VERSION ""

NS_ :

BS_:

BU_: ICC_ICE DVR EPC BBCM PCL PLG EAMP CMSM SBOX AVAS FLZCU RXCU_HCU CGW TBOX BNCM CWC FRZCU

BO_ 819 ADS_4: 48 CGW
 SG_ ADS_4_CRC1 : 7|8@0+ (1,0) [0|255] ""  ICC_ICE
 SG_ ADS_4_RollgCntr1 : 11|4@0+ (1,0) [0|14] ""  ICC_ICE
 SG_ ADS_4_Resd1 : 15|4@0+ (1,0) [0|15] ""  ICC_ICE
 SG_ ADS_4_AEBStatus : 19|3@0+ (1,0) [0|7] ""  ICC_ICE
 SG_ ADS_4_ACCSts : 23|4@0+ (1,0) [0|15] ""  ICC_ICE
 SG_ ADS_4_TimeGapSet : 26|3@0+ (1,0) [0|7] ""  ICC_ICE
 SG_ ADS_4_FcwMode : 29|3@0+ (1,0) [0|7] ""  ICC_ICE
 SG_ ADS_4_AEBReqType : 16|3@0+ (1,0) [0|7] ""  ICC_ICE
 SG_ ADS_4_SetSpd : 39|8@0+ (1,0) [0|255] "kph"  ICC_ICE
 SG_ ADS_4_DAIStatus : 41|2@0+ (1,0) [0|3] ""  ICC_ICE
 SG_ ADS_4_ACCTextMessage : 45|4@0+ (1,0) [0|15] ""  ICC_ICE
 SG_ ADS_4_LongiTakeOverReq : 46|1@0+ (1,0) [0|1] ""  ICC_ICE
 SG_ ADS_4_SetSpdUnit : 47|1@0+ (1,0) [0|1] ""  ICC_ICE
 SG_ ADS_4_GoNotifier : 50|3@0+ (1,0) [0|7] ""  ICC_ICE
 SG_ ADS_4_DAISts : 52|2@0+ (1,0) [0|3] ""  ICC_ICE
 SG_ ADS_4_Radar_textinfo : 55|3@0+ (1,0) [0|7] ""  ICC_ICE
 SG_ ADS_4_SCF_PopoverReq : 57|1@0+ (1,0) [0|1] ""  ICC_ICE
 SG_ ADS_4_DrvrCfmSCFDispFb : 58|1@0+ (1,0) [0|1] ""  ICC_ICE
 SG_ ADS_4_SCF_SpdLimUnit : 60|2@0+ (1,0) [0|3] ""  ICC_ICE
 SG_ ADS_4_SCF_SpdLimSts : 63|3@0+ (1,0) [0|7] ""  ICC_ICE
 SG_ ADS_4_CRC2 : 71|8@0+ (1,0) [0|255] ""  ICC_ICE
 SG_ ADS_4_RollgCntr2 : 75|4@0+ (1,0) [0|14] ""  ICC_ICE
 SG_ ADS_4_Resd2 : 79|4@0+ (1,0) [0|15] ""  ICC_ICE
 SG_ ADS_4_ACCObjTyp : 83|4@0+ (1,0) [0|15] ""  ICC_ICE
 SG_ ADS_4_FrntFarObjTyp : 87|4@0+ (1,0) [0|15] ""  ICC_ICE
 SG_ ADS_4_ACCObjLgtDstX : 95|8@0+ (0.5,0) [0|127] "m"  ICC_ICE
 SG_ ADS_4_FrntFarObjID : 107|1@0+ (1,0) [0|1] ""  ICC_ICE
 SG_ ADS_4_Resd : 108|1@0+ (1,0) [0|1] ""  ICC_ICE
 SG_ ADS_4_ACCObjID : 109|1@0+ (1,0) [0|1] ""  ICC_ICE
 SG_ ADS_4_ACCObjHozDstY : 103|10@0+ (0.1,-50) [-50|50] "m"  ICC_ICE
 SG_ ADS_4_FrntFarObjHozDstY : 105|10@0+ (0.1,-50) [-50|50] "m"  ICC_ICE
 SG_ ADS_4_FrntFarObjLgtDstX : 127|8@0+ (0.5,0) [0|127] "m"  ICC_ICE
 SG_ ADS_4_CRC3 : 135|8@0+ (1,0) [0|255] ""  ICC_ICE
 SG_ ADS_4_RollgCntr3 : 139|4@0+ (1,0) [0|14] ""  ICC_ICE
 SG_ ADS_4_Resd3 : 143|4@0+ (1,0) [0|15] ""  ICC_ICE
 SG_ ADS_4_Resd_1 : 146|1@0+ (1,0) [0|1] ""  ICC_ICE
 SG_ ADS_4_LeObjID : 147|1@0+ (1,0) [0|1] ""  ICC_ICE
 SG_ ADS_4_LeObjTyp : 151|4@0+ (1,0) [0|15] ""  ICC_ICE
 SG_ ADS_4_LeObjHozDstY : 145|10@0+ (0.1,-50) [-50|50] "m"  ICC_ICE
 SG_ ADS_4_LeObjLgtDstX : 167|8@0+ (0.5,0) [0|127] "m"  ICC_ICE
 SG_ ADS_4_RiObjID : 171|1@0+ (1,0) [0|1] ""  ICC_ICE
 SG_ ADS_4_RiObjTyp : 175|4@0+ (1,0) [0|15] ""  ICC_ICE
 SG_ ADS_4_RiObjHozDstY : 169|10@0+ (0.1,-50) [-50|50] "m"  ICC_ICE
 SG_ ADS_4_RiObjLgtDstX : 191|8@0+ (0.5,0) [0|127] "m"  ICC_ICE
 SG_ ADS_4_CRC4 : 199|8@0+ (1,0) [0|255] ""  ICC_ICE
 SG_ ADS_4_RollgCntr4 : 203|4@0+ (1,0) [0|14] ""  ICC_ICE
 SG_ ADS_4_Resd4 : 207|4@0+ (1,0) [0|15] ""  ICC_ICE
 SG_ ADS_4_SCFSwtSet : 210|2@0+ (1,0) [0|3] ""  ICC_ICE
 SG_ ADS_4_AEBSettingSt : 212|2@0+ (1,0) [0|3] ""  ICC_ICE
 SG_ ADS_4_FCWSettingSt : 215|3@0+ (1,0) [0|7] ""  ICC_ICE
 SG_ ADS_4_DAISwtSet : 223|2@0+ (1,0) [0|3] ""  ICC_ICE
 SG_ ADS_4_CruiseAccelerateSts : 221|2@0+ (1,0) [0|3] ""  ICC_ICE

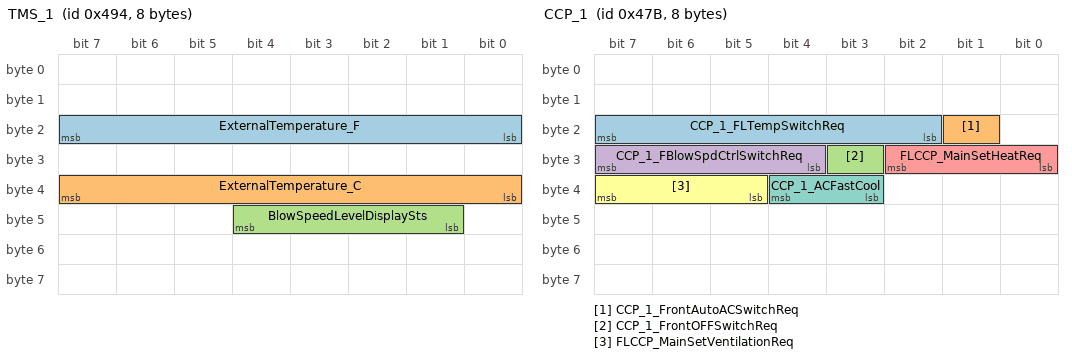
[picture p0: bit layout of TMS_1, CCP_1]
BO_ 1172 TMS_1: 8 CGW
 SG_ ExternalTemperature_F : 23|8@0+ (1,-67) [-67|158] "°F"  ICC_ICE,EPC
 SG_ ExternalTemperature_C : 39|8@0+ (0.5,-40) [-40|85] "°C"  ICC_ICE,EPC
 SG_ BlowSpeedLevelDisplaySts : 44|4@0+ (1,0) [0|15] ""  ICC_ICE,EAMP

BO_ 1147 CCP_1: 8 CGW
 SG_ CCP_1_FLTempSwitchReq : 23|6@0+ (0.5,15.5) [15.5|30.5] "℃"  ICC_ICE
 SG_ CCP_1_FrontAutoACSwitchReq : 17|1@0+ (1,0) [0|1] ""  ICC_ICE
 SG_ CCP_1_FrontOFFSwitchReq : 27|1@0+ (1,0) [0|1] ""  ICC_ICE
 SG_ CCP_1_FBlowSpdCtrlSwitchReq : 31|4@0+ (1,0) [0|15] ""  ICC_ICE
 SG_ FLCCP_MainSetHeatReq : 26|3@0+ (1,0) [0|7] ""  ICC_ICE
 SG_ FLCCP_MainSetVentilationReq : 39|3@0+ (1,0) [0|7] ""  ICC_ICE
 SG_ CCP_1_ACFastCool : 36|2@0+ (1,0) [0|3] ""  ICC_ICE

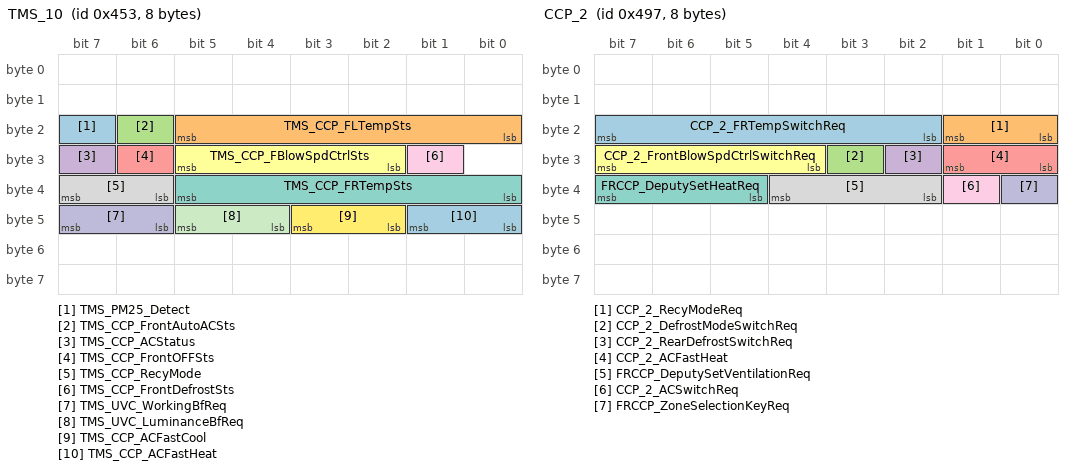
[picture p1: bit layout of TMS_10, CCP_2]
BO_ 1107 TMS_10: 8 CGW
 SG_ TMS_PM25_Detect : 23|1@0+ (1,0) [0|1] ""  ICC_ICE
 SG_ TMS_CCP_FLTempSts : 21|6@0+ (0.5,15.5) [15.5|30.5] "℃"  ICC_ICE
 SG_ TMS_CCP_FrontAutoACSts : 22|1@0+ (1,0) [0|1] ""  ICC_ICE
 SG_ TMS_CCP_ACStatus : 31|1@0+ (1,0) [0|1] ""  ICC_ICE
 SG_ TMS_CCP_FrontOFFSts : 30|1@0+ (1,0) [0|1] ""  ICC_ICE
 SG_ TMS_CCP_FBlowSpdCtrlSts : 29|4@0+ (1,0) [0|15] ""  ICC_ICE
 SG_ TMS_CCP_FRTempSts : 37|6@0+ (0.5,15.5) [15.5|30.5] "℃"  ICC_ICE
 SG_ TMS_CCP_RecyMode : 39|2@0+ (1,0) [0|3] ""  ICC_ICE
 SG_ TMS_CCP_FrontDefrostSts : 25|1@0+ (1,0) [0|1] ""  ICC_ICE
 SG_ TMS_UVC_WorkingBfReq : 47|2@0+ (1,0) [0|3] ""  ICC_ICE
 SG_ TMS_UVC_LuminanceBfReq : 45|2@0+ (1,0) [0|3] ""  ICC_ICE
 SG_ TMS_CCP_ACFastCool : 43|2@0+ (1,0) [0|3] ""  ICC_ICE
 SG_ TMS_CCP_ACFastHeat : 41|2@0+ (1,0) [0|3] ""  ICC_ICE

BO_ 1175 CCP_2: 8 CGW
 SG_ CCP_2_FRTempSwitchReq : 23|6@0+ (0.5,15.5) [15.5|30.5] "℃"  ICC_ICE
 SG_ CCP_2_RecyModeReq : 17|2@0+ (1,0) [0|3] ""  ICC_ICE
 SG_ CCP_2_DefrostModeSwitchReq : 27|1@0+ (1,0) [0|1] ""  ICC_ICE
 SG_ CCP_2_RearDefrostSwitchReq : 26|1@0+ (1,0) [0|1] ""  ICC_ICE
 SG_ CCP_2_ACFastHeat : 25|2@0+ (1,0) [0|3] ""  ICC_ICE
 SG_ CCP_2_FrontBlowSpdCtrlSwitchReq : 31|4@0+ (1,0) [0|15] ""  ICC_ICE
 SG_ FRCCP_DeputySetHeatReq : 39|3@0+ (1,0) [0|7] ""  ICC_ICE
 SG_ FRCCP_DeputySetVentilationReq : 36|3@0+ (1,0) [0|7] ""  ICC_ICE
 SG_ CCP_2_ACSwitchReq : 33|1@0+ (1,0) [0|1] ""  ICC_ICE
 SG_ FRCCP_ZoneSelectionKeyReq : 32|1@0+ (1,0) [0|1] ""  ICC_ICE

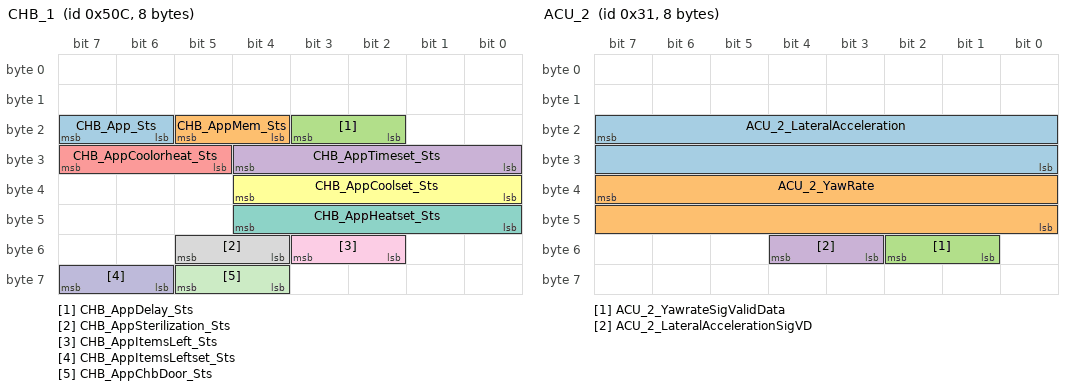
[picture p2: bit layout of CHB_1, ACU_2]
BO_ 1292 CHB_1: 8 CGW
 SG_ CHB_App_Sts : 23|2@0+ (1,0) [0|3] ""  ICC_ICE
 SG_ CHB_AppMem_Sts : 21|2@0+ (1,0) [0|3] ""  ICC_ICE
 SG_ CHB_AppDelay_Sts : 19|2@0+ (1,0) [0|3] ""  ICC_ICE
 SG_ CHB_AppTimeset_Sts : 28|5@0+ (1,0) [0|31] "h"  ICC_ICE
 SG_ CHB_AppCoolorheat_Sts : 31|3@0+ (1,0) [0|7] ""  ICC_ICE
 SG_ CHB_AppCoolset_Sts : 36|5@0+ (1,0) [0|31] ""  ICC_ICE
 SG_ CHB_AppHeatset_Sts : 44|5@0+ (1,0) [0|31] ""  ICC_ICE
 SG_ CHB_AppSterilization_Sts : 53|2@0+ (1,0) [0|3] ""  ICC_ICE
 SG_ CHB_AppItemsLeft_Sts : 51|2@0+ (1,0) [0|3] ""  ICC_ICE
 SG_ CHB_AppItemsLeftset_Sts : 63|2@0+ (1,0) [0|3] ""  ICC_ICE
 SG_ CHB_AppChbDoor_Sts : 61|2@0+ (1,0) [0|3] ""  ICC_ICE

BO_ 49 ACU_2: 8 CGW
 SG_ ACU_2_LateralAcceleration : 23|16@0+ (0.001,-2) [-2|2] "g"  ICC_ICE
 SG_ ACU_2_YawRate : 39|16@0+ (0.01,-180) [-180|180] "deg/sec"  ICC_ICE
 SG_ ACU_2_YawrateSigValidData : 50|2@0+ (1,0) [0|3] ""  ICC_ICE
 SG_ ACU_2_LateralAccelerationSigVD : 52|2@0+ (1,0) [0|3] ""  ICC_ICE

BO_ 1024 FRZCU_13: 64 CGW
 SG_ CSunshadeSts : 23|3@0+ (1,0) [0|7] ""  ICC_ICE
 SG_ CSunshadePercentSts : 20|4@0+ (1,0) [0|15] ""  ICC_ICE
 SG_ FRZCU_SeatHeatLvlFR2 : 31|4@0+ (1,0) [0|15] ""  ICC_ICE
 SG_ FRZCU_SeatVentLvlFR2 : 27|4@0+ (1,0) [0|15] ""  ICC_ICE
 SG_ FRZCU_SeatVentLvlRR2 : 39|4@0+ (1,0) [0|15] ""  ICC_ICE
 SG_ FRZCU_SeatHeatLvlRR2 : 35|4@0+ (1,0) [0|15] ""  ICC_ICE
 SG_ FRZCU_ContainerlightSts : 47|2@0+ (1,0) [0|3] ""  ICC_ICE
 SG_ FRZCU_FRWinThermalSts : 45|1@0+ (1,0) [0|1] ""  ICC_ICE
 SG_ FRZCU_RRWinThermalSts : 44|1@0+ (1,0) [0|1] ""  ICC_ICE
 SG_ FRZCU_CSunshadeThermalSts : 43|1@0+ (1,0) [0|1] ""  ICC_ICE
 SG_ FRZCU_ADSLightSts : 49|2@0+ (1,0) [0|3] ""  ICC_ICE
 SG_ FRZCU_PasgerSeatMovFailCause : 61|4@0+ (1,0) [0|15] ""  ICC_ICE
 SG_ FRZCU_QueenSeatEnterSts : 57|2@0+ (1,0) [0|3] ""  ICC_ICE
 SG_ FRZCU_QueenSeatMovFailCause : 87|4@0+ (1,0) [0|15] ""  ICC_ICE
 SG_ FRZCU_QueenSeatSts : 83|2@0+ (1,0) [0|3] ""  ICC_ICE,BBCM
 SG_ CSunshadeLearnedSts : 93|2@0+ (1,0) [0|3] ""  ICC_ICE
 SG_ CSunshadePosn : 103|7@0+ (1,0) [0|100] "%"  ICC_ICE
 SG_ FRZCU_OnekeyHVoffSwtst : 41|2@0+ (1,0) [0|3] ""  ICC_ICE

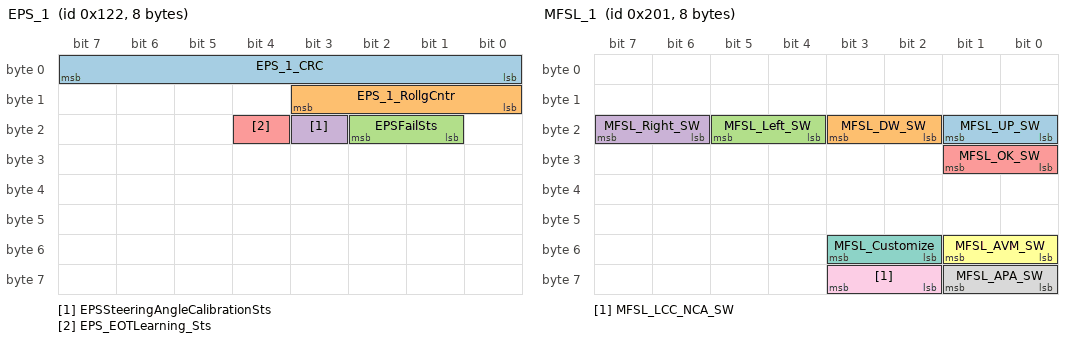
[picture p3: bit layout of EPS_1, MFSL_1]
BO_ 290 EPS_1: 8 CGW
 SG_ EPS_1_CRC : 7|8@0+ (1,0) [0|255] ""  ICC_ICE
 SG_ EPS_1_RollgCntr : 11|4@0+ (1,0) [0|14] ""  ICC_ICE
 SG_ EPSFailSts : 18|2@0+ (1,0) [0|3] ""  ICC_ICE
 SG_ EPSSteeringAngleCalibrationSts : 19|1@0+ (1,0) [0|1] ""  ICC_ICE
 SG_ EPS_EOTLearning_Sts : 20|1@0+ (1,0) [0|1] ""  ICC_ICE

BO_ 513 MFSL_1: 8 CGW
 SG_ MFSL_UP_SW : 17|2@0+ (1,0) [0|3] ""  ICC_ICE
 SG_ MFSL_DW_SW : 19|2@0+ (1,0) [0|3] ""  ICC_ICE
 SG_ MFSL_Left_SW : 21|2@0+ (1,0) [0|3] ""  ICC_ICE
 SG_ MFSL_Right_SW : 23|2@0+ (1,0) [0|3] ""  ICC_ICE
 SG_ MFSL_OK_SW : 25|2@0+ (1,0) [0|3] ""  ICC_ICE
 SG_ MFSL_AVM_SW : 49|2@0+ (1,0) [0|3] ""  ICC_ICE
 SG_ MFSL_Customize : 51|2@0+ (1,0) [0|3] ""  ICC_ICE
 SG_ MFSL_APA_SW : 57|2@0+ (1,0) [0|3] ""  ICC_ICE
 SG_ MFSL_LCC_NCA_SW : 59|2@0+ (1,0) [0|3] ""  ICC_ICE

BO_ 1152 TBOX_8: 16 CGW
 SG_ TBOX_PetmodeSetTemperature : 118|5@0+ (0.5,15.5) [15.5|30.5] "℃"  ICC_ICE

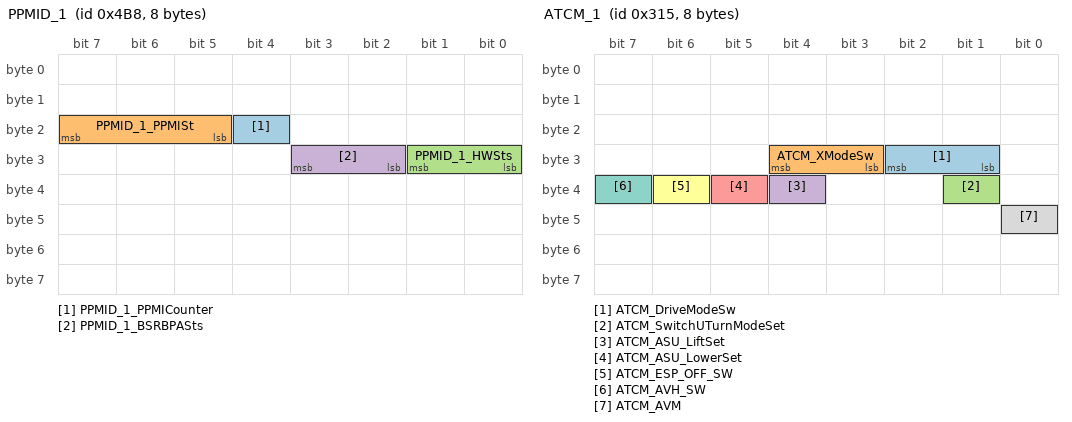
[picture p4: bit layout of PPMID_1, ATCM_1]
BO_ 1208 PPMID_1: 8 CGW
 SG_ PPMID_1_PPMICounter : 20|1@0+ (1,0) [0|1] ""  ICC_ICE
 SG_ PPMID_1_PPMISt : 23|3@0+ (1,0) [0|7] ""  ICC_ICE
 SG_ PPMID_1_HWSts : 25|2@0+ (1,0) [0|3] ""  ICC_ICE
 SG_ PPMID_1_BSRBPASts : 27|2@0+ (1,0) [0|3] ""  ICC_ICE

BO_ 794 ADS_COM_3: 24 CGW
 SG_ ADS_3_ICAStatus : 23|3@0+ (1,0) [0|7] ""  ICC_ICE
 SG_ ADS_3_ICATextinfo : 19|4@0+ (1,0) [0|15] ""  ICC_ICE
 SG_ ADS_3_ACCSts : 31|4@0+ (1,0) [0|15] ""  ICC_ICE
 SG_ ADS_3_DriverHandsoffWarning : 27|3@0+ (1,0) [0|7] ""  ICC_ICE
 SG_ ADS_3_LKSMod : 36|2@0+ (1,0) [0|3] ""  ICC_ICE
 SG_ ADS_3_LKSSts : 34|3@0+ (1,0) [0|7] ""  ICC_ICE
 SG_ ADS_3_ELKSts : 47|3@0+ (1,0) [0|7] ""  ICC_ICE
 SG_ ADS_3_LKSLeftTrackingSt : 44|2@0+ (1,0) [0|3] ""  ICC_ICE
 SG_ ADS_3_LKSRightTrackingSt : 42|2@0+ (1,0) [0|3] ""  ICC_ICE
 SG_ ADS_3_ELKLeftActiveSt : 55|2@0+ (1,0) [0|3] ""  ICC_ICE
 SG_ ADS_3_ELKRightActiveSt : 53|2@0+ (1,0) [0|3] ""  ICC_ICE

BO_ 1155 ASU_3: 16 CGW
 SG_ ASU_3_horizontalSts : 55|2@0+ (1,0) [0|3] ""  ICC_ICE
 SG_ ASU_3_horizontalmodeFb : 58|3@0+ (1,0) [0|7] ""  ICC_ICE

BO_ 789 ATCM_1: 8 CGW
 SG_ ATCM_DriveModeSw : 26|2@0+ (1,0) [0|3] ""  ICC_ICE
 SG_ ATCM_XModeSw : 28|2@0+ (1,0) [0|3] ""  ICC_ICE
 SG_ ATCM_SwitchUTurnModeSet : 33|1@0+ (1,0) [0|1] ""  ICC_ICE
 SG_ ATCM_ASU_LiftSet : 36|1@0+ (1,0) [0|1] ""  ICC_ICE
 SG_ ATCM_ASU_LowerSet : 37|1@0+ (1,0) [0|1] ""  ICC_ICE
 SG_ ATCM_ESP_OFF_SW : 38|1@0+ (1,0) [0|1] ""  ICC_ICE
 SG_ ATCM_AVH_SW : 39|1@0+ (1,0) [0|1] ""  ICC_ICE
 SG_ ATCM_AVM : 40|1@0+ (1,0) [0|1] ""  ICC_ICE

BO_ 1214 BNCM_16: 32 CGW
 SG_ BNCM_16_CRC1 : 7|8@0+ (1,0) [0|255] ""  ICC_ICE
 SG_ BNCM_16_RollgCntr1 : 11|4@0+ (1,0) [0|14] ""  ICC_ICE
 SG_ BNCM_16_Resd1 : 15|4@0+ (1,0) [0|15] ""  ICC_ICE
 SG_ BNCM_16_CMD : 23|16@0+ (1,0) [0|65535] ""  ICC_ICE
 SG_ BNCM_16_PDU1 : 39|64@0+ (1,0) [0|1.84467440737096E+19] ""  ICC_ICE
 SG_ BNCM_16_PDU2 : 103|64@0+ (1,0) [0|1.84467440737096E+19] ""  ICC_ICE
 SG_ BNCM_16_PDU3 : 167|64@0+ (1,0) [0|1.84467440737096E+19] ""  ICC_ICE
 SG_ BNCM_16_PDU4 : 231|32@0+ (1,0) [0|4294967295] ""  ICC_ICE

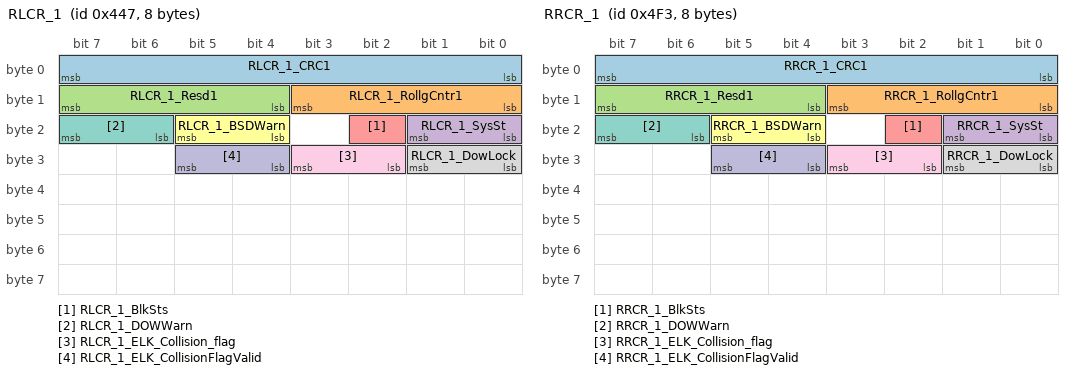
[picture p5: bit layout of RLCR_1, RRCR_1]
BO_ 1095 RLCR_1: 8 CGW
 SG_ RLCR_1_CRC1 : 7|8@0+ (1,0) [0|255] ""  ICC_ICE
 SG_ RLCR_1_RollgCntr1 : 11|4@0+ (1,0) [0|14] ""  ICC_ICE
 SG_ RLCR_1_Resd1 : 15|4@0+ (1,0) [0|15] ""  ICC_ICE
 SG_ RLCR_1_SysSt : 17|2@0+ (1,0) [0|3] ""  ICC_ICE
 SG_ RLCR_1_BlkSts : 18|1@0+ (1,0) [0|1] ""  ICC_ICE
 SG_ RLCR_1_BSDWarn : 21|2@0+ (1,0) [0|3] ""  ICC_ICE
 SG_ RLCR_1_DOWWarn : 23|2@0+ (1,0) [0|3] ""  ICC_ICE
 SG_ RLCR_1_DowLock : 25|2@0+ (1,0) [0|3] ""  ICC_ICE
 SG_ RLCR_1_ELK_Collision_flag : 27|2@0+ (1,0) [0|3] ""  ICC_ICE
 SG_ RLCR_1_ELK_CollisionFlagValid : 29|2@0+ (1,0) [0|3] ""  ICC_ICE

BO_ 1267 RRCR_1: 8 CGW
 SG_ RRCR_1_CRC1 : 7|8@0+ (1,0) [0|255] ""  ICC_ICE
 SG_ RRCR_1_RollgCntr1 : 11|4@0+ (1,0) [0|14] ""  ICC_ICE
 SG_ RRCR_1_Resd1 : 15|4@0+ (1,0) [0|15] ""  ICC_ICE
 SG_ RRCR_1_SysSt : 17|2@0+ (1,0) [0|3] ""  ICC_ICE
 SG_ RRCR_1_BlkSts : 18|1@0+ (1,0) [0|1] ""  ICC_ICE
 SG_ RRCR_1_BSDWarn : 21|2@0+ (1,0) [0|3] ""  ICC_ICE
 SG_ RRCR_1_DOWWarn : 23|2@0+ (1,0) [0|3] ""  ICC_ICE
 SG_ RRCR_1_DowLock : 25|2@0+ (1,0) [0|3] ""  ICC_ICE
 SG_ RRCR_1_ELK_Collision_flag : 27|2@0+ (1,0) [0|3] ""  ICC_ICE
 SG_ RRCR_1_ELK_CollisionFlagValid : 29|2@0+ (1,0) [0|3] ""  ICC_ICE

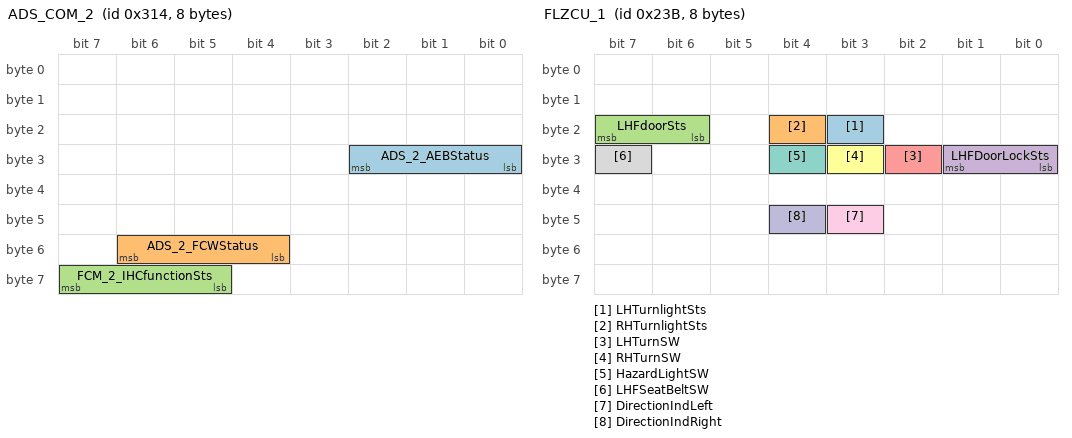
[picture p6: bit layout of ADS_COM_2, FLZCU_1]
BO_ 788 ADS_COM_2: 8 CGW
 SG_ ADS_2_AEBStatus : 26|3@0+ (1,0) [0|6] ""  ICC_ICE
 SG_ ADS_2_FCWStatus : 54|3@0+ (1,0) [0|7] ""  ICC_ICE
 SG_ FCM_2_IHCfunctionSts : 63|3@0+ (1,0) [0|7] ""  ICC_ICE

BO_ 571 FLZCU_1: 8 FLZCU
 SG_ LHTurnlightSts : 19|1@0+ (1,0) [0|1] ""  ICC_ICE,DVR
 SG_ RHTurnlightSts : 20|1@0+ (1,0) [0|1] ""  ICC_ICE,DVR
 SG_ LHFdoorSts : 23|2@0+ (1,0) [0|3] ""  ICC_ICE,EPC,BBCM,PCL,PLG,CMSM
 SG_ LHFDoorLockSts : 25|2@0+ (1,0) [0|3] ""  ICC_ICE,EPC,BBCM,PCL,PLG
 SG_ LHTurnSW : 26|1@0+ (1,0) [0|1] ""  ICC_ICE
 SG_ RHTurnSW : 27|1@0+ (1,0) [0|1] ""  ICC_ICE
 SG_ HazardLightSW : 28|1@0+ (1,0) [0|1] ""  ICC_ICE
 SG_ LHFSeatBeltSW : 31|1@0+ (1,0) [0|1] ""  ICC_ICE
 SG_ DirectionIndLeft : 43|1@0+ (1,0) [0|1] ""  ICC_ICE
 SG_ DirectionIndRight : 44|1@0+ (1,0) [0|1] ""  ICC_ICE

BO_ 699 RZCU_2: 8 FLZCU
 SG_ LHRdoorSts : 21|2@0+ (1,0) [0|3] ""  ICC_ICE,EPC,BBCM,PCL,CMSM

BO_ 787 FRZCU_14: 16 CGW
 SG_ ChrgHoodSts : 23|1@0+ (1,0) [0|1] ""  ICC_ICE
 SG_ FRZCU_FRSitPosnSts : 22|2@0+ (1,0) [0|3] ""  ICC_ICE

BO_ 524 ADS_6: 48 CGW
 SG_ ADS_6_Customize_buttonsFB : 19|3@0+ (1,0) [0|7] ""  ICC_ICE

BO_ 572 ONEBOX_7: 48 CGW
 SG_ ONEBOX_7_TAB_HighTemp : 49|1@0+ (1,0) [0|1] ""  ICC_ICE
 SG_ ONEBOX_7_TAB_Active : 51|2@0+ (1,0) [0|3] ""  ICC_ICE
 SG_ ONEBOX_7_BSW_Active : 60|2@0+ (1,0) [0|3] ""  ICC_ICE
 SG_ ONEBOX_7_iCCO_TgtVel : 151|8@0+ (0.1,0) [0|20] ""  ICC_ICE

BO_ 783 ADS_COM_1: 8 CGW
 SG_ ADCC_SysReadySts : 43|1@0+ (1,0) [0|1] ""  ICC_ICE

BO_ 1110 IMMO_ICC_11: 8 CGW
 SG_ IMMO_Chall_ICC : 7|64@0+ (1,0) [0|1.84467440737096E+19] ""  ICC_ICE

BO_ 1149 IMMO_VCC_12: 8 CGW
 SG_ IMMO_Teach_VCC : 7|64@0+ (1,0) [0|1.84467440737096E+19] ""  ICC_ICE

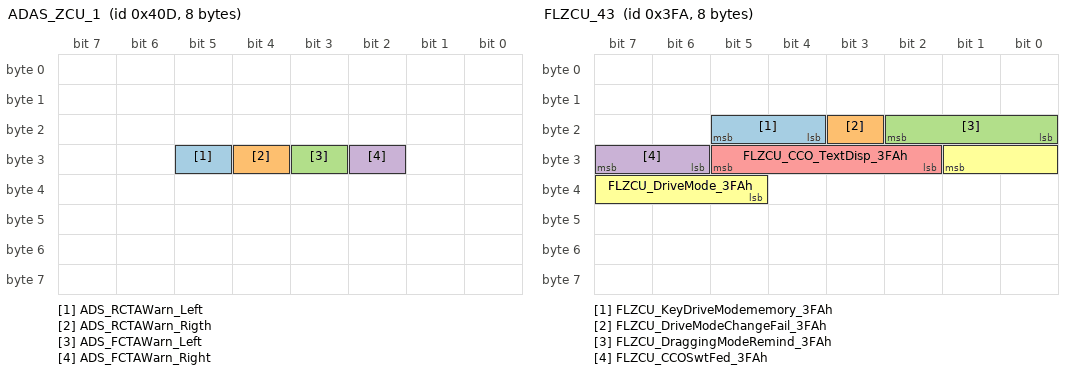
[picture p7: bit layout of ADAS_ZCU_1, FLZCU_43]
BO_ 1037 ADAS_ZCU_1: 8 CGW
 SG_ ADS_RCTAWarn_Left : 29|1@0+ (1,0) [0|1] ""  ICC_ICE
 SG_ ADS_RCTAWarn_Rigth : 28|1@0+ (1,0) [0|1] ""  ICC_ICE
 SG_ ADS_FCTAWarn_Left : 27|1@0+ (1,0) [0|1] ""  ICC_ICE
 SG_ ADS_FCTAWarn_Right : 26|1@0+ (1,0) [0|1] ""  ICC_ICE

BO_ 943 CSA_3: 32 CGW
 SG_ CSA_3_CRC1 : 7|8@0+ (1,0) [0|255] ""  ICC_ICE
 SG_ CSA_3_RollgCntr1 : 11|4@0+ (1,0) [0|14] ""  ICC_ICE
 SG_ CSA_3_Resd1 : 15|4@0+ (1,0) [0|15] ""  ICC_ICE
 SG_ FlwheelBearing : 23|12@0+ (0.001,0) [0|4.095] "t"  ICC_ICE
 SG_ FrwheelBearing : 27|12@0+ (0.001,0) [0|4.095] "t"  ICC_ICE
 SG_ BlwheelBearing : 47|12@0+ (0.001,0) [0|4.095] "t"  ICC_ICE
 SG_ BrwheelBearing : 51|12@0+ (0.001,0) [0|4.095] "t"  ICC_ICE
 SG_ CSA_3_CRC2 : 71|8@0+ (1,0) [0|255] ""  ICC_ICE
 SG_ CSA_3_RollgCntr2 : 75|4@0+ (1,0) [0|14] ""  ICC_ICE
 SG_ VehicleBearing_kg : 87|12@0+ (1,0) [0|4095] "kg"  ICC_ICE
 SG_ VehicleBearing_lb : 91|14@0+ (1,0) [0|16383] "lb"  ICC_ICE
 SG_ GoodsWeight_kg : 109|12@0+ (1,0) [0|4095] "kg"  ICC_ICE
 SG_ Goods_Weight_Ratio : 113|10@0+ (0.1,0) [0|100] "%"  ICC_ICE
 SG_ CSA_3_CRC3 : 135|8@0+ (1,0) [0|255] ""  ICC_ICE
 SG_ CSA_3_RollgCntr3 : 139|4@0+ (1,0) [0|14] ""  ICC_ICE
 SG_ CSA_3_Resd3 : 143|4@0+ (1,0) [0|15] ""  ICC_ICE
 SG_ GoodsWeight_lb : 151|14@0+ (1,0) [0|16383] "lb"  ICC_ICE
 SG_ OverWeightValue_kg : 153|12@0+ (1,0) [0|4095] "kg"  ICC_ICE
 SG_ OverWeightValue_lb : 173|14@0+ (1,0) [0|16383] "lb"  ICC_ICE
 SG_ OverWeightRatio : 191|3@0+ (1,0) [0|7] "%"  ICC_ICE
 SG_ OverWeightWarning : 188|1@0+ (1,0) [0|1] ""  ICC_ICE
 SG_ OverLoadWarnShieldSetFed : 187|2@0+ (1,0) [0|3] ""  ICC_ICE
 SG_ Fraxlebearingrate : 199|8@0+ (1,0) [0|100] "%"  ICC_ICE

BO_ 1120 FLZCU_3: 8 FLZCU
 SG_ RLHS_2_AmbBrightness : 19|12@0+ (20,0) [0|81880] "Lux"  ICC_ICE
 SG_ RLHS_LiSwithReason : 49|2@0+ (1,0) [0|3] ""  ICC_ICE

BO_ 850 ASU_6: 32 CGW
 SG_ ASU_6_HMIFailFb_JT : 23|4@0+ (1,0) [0|15] ""  ICC_ICE
 SG_ ASU_inflate_352h : 43|2@0+ (1,0) [0|3] ""  ICC_ICE
 SG_ ASU_trekthrough_352h : 47|2@0+ (1,0) [0|3] ""  ICC_ICE
 SG_ ASU_undergroundmode_352h : 45|2@0+ (1,0) [0|3] ""  ICC_ICE

BO_ 1199 TCM_1: 8 CGW
 SG_ TCM_1_TrailerSts : 16|1@0+ (1,0) [0|1] ""  ICC_ICE

BO_ 1131 TCU_46Bh: 16 CGW
 SG_ ClutchTemperature_46Bh : 63|2@0+ (1,0) [0|3] ""  ICC_ICE
 SG_ GBFaultstatus_46Bh : 61|2@0+ (1,0) [0|3] ""  ICC_ICE
 SG_ GBPositoionDisplay_46Bh : 55|5@0+ (1,0) [0|31] ""  ICC_ICE

BO_ 1060 TCU_424h: 64 CGW
 SG_ InforDisplay_424h : 38|4@0+ (1,0) [0|15] ""  ICC_ICE

BO_ 1129 EMS_COM_469h: 16 CGW
 SG_ EngineCoolantTemp_469h : 23|8@0+ (0.75,-48) [-48|142.5] "℃"  ICC_ICE
 SG_ EngineSpeed_469h : 87|11@0+ (4,0) [0|8000] "rpm"  ICC_ICE
 SG_ EngineSpeedValidData_469h : 92|2@0+ (1,0) [0|3] ""  ICC_ICE

BO_ 1128 EMS_ICC_468h: 24 CGW
 SG_ PromptMesg_468h : 31|2@0+ (1,0) [0|3] ""  ICC_ICE

BO_ 1018 FLZCU_43: 8 FLZCU
 SG_ FLZCU_KeyDriveModememory_3FAh : 21|2@0+ (1,0) [0|3] ""  ICC_ICE
 SG_ FLZCU_DriveModeChangeFail_3FAh : 19|1@0+ (1,0) [0|1] ""  ICC_ICE
 SG_ FLZCU_DraggingModeRemind_3FAh : 18|3@0+ (1,0) [0|7] ""  ICC_ICE
 SG_ FLZCU_CCOSwtFed_3FAh : 31|2@0+ (1,0) [0|3] ""  ICC_ICE
 SG_ FLZCU_CCO_TextDisp_3FAh : 29|4@0+ (1,0) [0|15] ""  ICC_ICE
 SG_ FLZCU_DriveMode_3FAh : 25|5@0+ (1,0) [0|31] ""  ICC_ICE

BO_ 1123 EMS_463h: 16 CGW
 SG_ ISS_Switch_Sts_463h : 21|2@0+ (1,0) [0|3] ""  ICC_ICE

BO_ 1972 Diag_FLZCU_RES: 64 FLZCU
 SG_ Diag_FLZCU_RES : 7|64@0+ (1,0) [0|1.84467440737096E+19] ""  ICC_ICE

BO_ 1844 Diag_FLZCU_REQ: 64 ICC_ICE
 SG_ Diag_FLZCU_REQ : 7|64@0+ (1,0) [0|1.84467440737096E+19] ""  FLZCU

BO_TX_BU_ 787 : CGW,FRZCU;
CM_ SG_ 819 ADS_4_CRC1 "Profile1A:E2E CRC (SAE J1850 CRC-8) for 8 Bytes
DataID:No ASIL requirements.Not configure
CRC Reserved.";
CM_ SG_ 819 ADS_4_RollgCntr1 "Profile1A:E2E Rolling message counter(the maximum value of Alive counter is 14)";
CM_ SG_ 819 ADS_4_Resd1 "Profile1A:E2E Reserved";
CM_ SG_ 819 ADS_4_AEBStatus "AEB功能状态";
CM_ SG_ 819 ADS_4_ACCSts "ACC功能状态";
CM_ SG_ 819 ADS_4_TimeGapSet "跟车时距";
CM_ SG_ 819 ADS_4_FcwMode "FCW功能状态";
CM_ SG_ 819 ADS_4_AEBReqType "AEB请求类型";
CM_ SG_ 819 ADS_4_SetSpd "巡航车速";
CM_ SG_ 819 ADS_4_DAIStatus "起步提醒功能状态";
CM_ SG_ 819 ADS_4_ACCTextMessage "ACC提示信息";
CM_ SG_ 819 ADS_4_LongiTakeOverReq "接管请求";
CM_ SG_ 819 ADS_4_SetSpdUnit "巡航车速单位";
CM_ SG_ 819 ADS_4_GoNotifier "起步提醒文言";
CM_ SG_ 819 ADS_4_DAISts "起步提醒功能执行状态";
CM_ SG_ 819 ADS_4_Radar_textinfo "雷达提示信息";
CM_ SG_ 819 ADS_4_SCF_PopoverReq "智能限速辅助弹窗提醒";
CM_ SG_ 819 ADS_4_DrvrCfmSCFDispFb "SCF 驾驶员确认信号 （确认后，setspeed变为摄像头限速值）";
CM_ SG_ 819 ADS_4_SCF_SpdLimUnit "智能限速辅助单位";
CM_ SG_ 819 ADS_4_SCF_SpdLimSts "智能限速辅助功能状态";
CM_ SG_ 819 ADS_4_CRC2 "Profile1A:E2E CRC (SAE J1850 CRC-8) for 8 Bytes
DataID:No ASIL requirements.Not configure
CRC Reserved.";
CM_ SG_ 819 ADS_4_RollgCntr2 "Profile1A:E2E Rolling message counter(the maximum value of Alive counter is 14)";
CM_ SG_ 819 ADS_4_Resd2 "Profile1A:E2E Reserved";
CM_ SG_ 819 ADS_4_ACCObjTyp "跟车目标类型";
CM_ SG_ 819 ADS_4_FrntFarObjTyp "前前车目标类型";
CM_ SG_ 819 ADS_4_ACCObjLgtDstX "跟车目标纵向距离";
CM_ SG_ 819 ADS_4_FrntFarObjID "前前车有效性";
CM_ SG_ 819 ADS_4_ACCObjID "跟车目标有效性";
CM_ SG_ 819 ADS_4_ACCObjHozDstY "跟车目标横向距离";
CM_ SG_ 819 ADS_4_FrntFarObjHozDstY "前前车横向距离";
CM_ SG_ 819 ADS_4_FrntFarObjLgtDstX "前前车纵向距离";
CM_ SG_ 819 ADS_4_CRC3 "Profile1A:E2E CRC (SAE J1850 CRC-8) for 8 Bytes
DataID:No ASIL requirements.Not configure
CRC Reserved.";
CM_ SG_ 819 ADS_4_RollgCntr3 "Profile1A:E2E Rolling message counter(the maximum value of Alive counter is 14)";
CM_ SG_ 819 ADS_4_Resd3 "Profile1A:E2E Reserved";
CM_ SG_ 819 ADS_4_LeObjID "左边车辆类型有效性";
CM_ SG_ 819 ADS_4_LeObjTyp "左边车辆类型";
CM_ SG_ 819 ADS_4_LeObjHozDstY "左边车辆横向距离";
CM_ SG_ 819 ADS_4_LeObjLgtDstX "左边车辆纵向距离";
CM_ SG_ 819 ADS_4_RiObjID "右边车辆类型有效性";
CM_ SG_ 819 ADS_4_RiObjTyp "右边车辆类型";
CM_ SG_ 819 ADS_4_RiObjHozDstY "右边车辆横向距离";
CM_ SG_ 819 ADS_4_RiObjLgtDstX "右边车辆纵向距离";
CM_ SG_ 819 ADS_4_CRC4 "Profile1A:E2E CRC (SAE J1850 CRC-8) for 8 Bytes
DataID:No ASIL requirements.Not configure
CRC Reserved.";
CM_ SG_ 819 ADS_4_RollgCntr4 "Profile1A:E2E Rolling message counter(the maximum value of Alive counter is 14)";
CM_ SG_ 819 ADS_4_Resd4 "Profile1A:E2E Reserved";
CM_ SG_ 819 ADS_4_SCFSwtSet "智能限速辅助反馈开关（预留默认开）";
CM_ SG_ 819 ADS_4_AEBSettingSt "AEB功能设置状态反馈";
CM_ SG_ 819 ADS_4_FCWSettingSt "FCW功能设置状态反馈";
CM_ SG_ 819 ADS_4_DAISwtSet "驶离提醒开关（预留默认开）";
CM_ SG_ 819 ADS_4_CruiseAccelerateSts "巡航跟车加减速状态指示，低配用于HMI显示";
CM_ SG_ 1172 ExternalTemperature_F "External_temperature（F）（外部温度（华氏度））";
CM_ SG_ 1172 ExternalTemperature_C "External_temperature（℃）
Invalid:_When_external_temperature_is_fail,_the_signal_value_is_0xFE.";
CM_ SG_ 1172 BlowSpeedLevelDisplaySts "Blow_Speed_Level_feedback
鼓风机档位
0xB:Auto后面要加这个属性";
CM_ SG_ 1147 CCP_1_FLTempSwitchReq "前排左侧温度调节,按下触摸到抬起一次，20ms信号有效的时候连发3帧，后期周期间隔100ms，按照当前状态发送";
CM_ SG_ 1147 CCP_1_FrontAutoACSwitchReq "前排自动功能";
CM_ SG_ 1147 CCP_1_FrontOFFSwitchReq "前排空调关闭";
CM_ SG_ 1147 CCP_1_FBlowSpdCtrlSwitchReq "前排风速";
CM_ SG_ 1147 FLCCP_MainSetHeatReq "主驾座椅加热";
CM_ SG_ 1147 FLCCP_MainSetVentilationReq "主驾座椅通风";
CM_ SG_ 1147 CCP_1_ACFastCool "一键制冷请求";
CM_ SG_ 1107 TMS_CCP_FLTempSts "前排左侧温度设置";
CM_ SG_ 1107 TMS_CCP_FrontAutoACSts "前排自动功能";
CM_ SG_ 1107 TMS_CCP_ACStatus "ACStatus
AC_状态";
CM_ SG_ 1107 TMS_CCP_FrontOFFSts "空调关闭";
CM_ SG_ 1107 TMS_CCP_FBlowSpdCtrlSts "前排风速设置";
CM_ SG_ 1107 TMS_CCP_FRTempSts "前排右侧温度设置";
CM_ SG_ 1107 TMS_CCP_RecyMode "内外循环";
CM_ SG_ 1107 TMS_CCP_FrontDefrostSts "前除霜";
CM_ SG_ 1107 TMS_UVC_WorkingBfReq "紫外线杀菌灯请求";
CM_ SG_ 1107 TMS_UVC_LuminanceBfReq "紫外线杀菌灯强度请求";
CM_ SG_ 1107 TMS_CCP_ACFastCool "一键制冷反馈";
CM_ SG_ 1107 TMS_CCP_ACFastHeat "一键制热反馈";
CM_ SG_ 1175 CCP_2_FRTempSwitchReq "前排右侧温度调节";
CM_ SG_ 1175 CCP_2_RecyModeReq "内外循环";
CM_ SG_ 1175 CCP_2_DefrostModeSwitchReq "前除霜";
CM_ SG_ 1175 CCP_2_RearDefrostSwitchReq "后除霜请求";
CM_ SG_ 1175 CCP_2_ACFastHeat "一键制热请求";
CM_ SG_ 1175 CCP_2_FrontBlowSpdCtrlSwitchReq "前排风速";
CM_ SG_ 1175 FRCCP_DeputySetHeatReq "副驾座椅加热";
CM_ SG_ 1175 FRCCP_DeputySetVentilationReq "副驾座椅通风";
CM_ SG_ 1175 CCP_2_ACSwitchReq "AC开关请求";
CM_ SG_ 1175 FRCCP_ZoneSelectionKeyReq "同步请求";
CM_ SG_ 1292 CHB_App_Sts "冰箱开关状态（捷途预留）";
CM_ SG_ 1292 CHB_AppMem_Sts "记忆开关状态";
CM_ SG_ 1292 CHB_AppDelay_Sts "延时开关状态";
CM_ SG_ 1292 CHB_AppTimeset_Sts "延时时间设置";
CM_ SG_ 1292 CHB_AppCoolorheat_Sts "制冷制热选择状态
冰箱工作模式（捷途使用）
0x0：无请求
0x1：制冷
0x2：制热
0x3：关
0x4：冷饮模式
0x5：冰淇淋模式
0x6：温奶模式
0x7：热饮模式";
CM_ SG_ 1292 CHB_AppCoolset_Sts "制冷温度设置
0xE~0x19:-18℃~-7℃（捷途预留）
0x1~0xD:-6℃~6℃（捷途使用）";
CM_ SG_ 1292 CHB_AppHeatset_Sts "制热温度调节设置";
CM_ SG_ 1292 CHB_AppSterilization_Sts "杀菌开关状态";
CM_ SG_ 1292 CHB_AppItemsLeft_Sts "物品遗留开关状态";
CM_ SG_ 1292 CHB_AppItemsLeftset_Sts "冰箱是否检测到物品的状态";
CM_ SG_ 1292 CHB_AppChbDoor_Sts "冰箱是门开关状态反馈信号";
CM_ SG_ 49 ACU_2_LateralAcceleration "Lateral acceleration signal
Sensor accuracy：0.0027680342857143g";
CM_ SG_ 49 ACU_2_YawRate "Yaw rate signal
Sensor accuracy：0.122189236 deg/s";
CM_ SG_ 49 ACU_2_YawrateSigValidData "Signal state for yawrate";
CM_ SG_ 49 ACU_2_LateralAccelerationSigVD "If hasn’t been calibrated, after initialization, this signal ‘s value is always 10(invalid).";
CM_ SG_ 1024 CSunshadeSts "天幕遮阳帘实际状态
(大屏动效-可显示开启和关闭的动画)";
CM_ SG_ 1024 CSunshadePercentSts "天幕遮阳帘开度百分比状态";
CM_ SG_ 1024 FRZCU_SeatHeatLvlFR2 "副驾座椅加热状态--捷途使用";
CM_ SG_ 1024 FRZCU_SeatVentLvlFR2 "副驾座椅通风状态--捷途使用";
CM_ SG_ 1024 FRZCU_SeatVentLvlRR2 "二排右侧座椅通风状态--捷途使用";
CM_ SG_ 1024 FRZCU_SeatHeatLvlRR2 "二排右侧座椅加热状态--捷途使用";
CM_ SG_ 1024 FRZCU_ContainerlightSts "货箱灯状态反馈（D01P)";
CM_ SG_ 1024 FRZCU_FRWinThermalSts "右前车窗热保护状态
0：未触发热保护
1：热保护触发中";
CM_ SG_ 1024 FRZCU_RRWinThermalSts "右后车窗热保护状态
0：未触发热保护
1：热保护触发中";
CM_ SG_ 1024 FRZCU_CSunshadeThermalSts "天幕遮阳帘热保护状态
0：未触发热保护
1：热保护触发中";
CM_ SG_ 1024 FRZCU_ADSLightSts "智驾小蓝灯开关状态
ADS进行相关的车模显示";
CM_ SG_ 1024 FRZCU_PasgerSeatMovFailCause "副驾调节失败原因
0x1:座椅未学习
0x2:触发防夹
0x3:硬开关未释放
0x4:副驾处于折叠状态
0x5:电机线路故障（开路、短路、霍尔丢失）
0x6:优先级不满足";
CM_ SG_ 1024 FRZCU_QueenSeatEnterSts "女王副驾进入状态反馈
0x1:调节中
0x2:调节成功（女王模式进入成功）
0x3:调节失败（女王模式进入失败）";
CM_ SG_ 1024 FRZCU_QueenSeatMovFailCause "女王副驾调节失败原因
0x1:座椅未学习
0x2:触发防夹
0x3:硬开关未释放
0x4:副驾处于折叠状态
0x5:电机线路故障（开路、短路、霍尔丢失）
0x6:优先级不满足
0x7:二排已展开
0x8:二排右侧座椅被占用
0x9:二排被打断";
CM_ SG_ 1024 FRZCU_QueenSeatSts "女王副驾状态反馈
0x0:无请求
0x1:已退出
0x2:已进入";
CM_ SG_ 1024 CSunshadeLearnedSts "遮阳帘学习状态，学习中大屏开关不可用";
CM_ SG_ 1024 CSunshadePosn "遮阳帘开度";
CM_ SG_ 1024 FRZCU_OnekeyHVoffSwtst "紧急下电开关状态反馈（法规要求，执行下高压，低压不变）";
CM_ SG_ 290 EPS_1_CRC "Profile1A:E2E CRC (SAE J1850 CRC-8) for 8 Bytes
DataID:0x002E";
CM_ SG_ 290 EPS_1_RollgCntr "Profile1A:E2E Rolling message counter(the maximum value of Alive counter is 14)";
CM_ SG_ 290 EPSFailSts "EPS Fail Status";
CM_ SG_ 290 EPSSteeringAngleCalibrationSts "EPS Steering Angle Calibration Status";
CM_ SG_ 290 EPS_EOTLearning_Sts "Indicates the status of EPS EOT(end of travel) learning, displayed on the DMC(ICM)";
CM_ SG_ 513 MFSL_APA_SW "APA开关";
CM_ SG_ 513 MFSL_LCC_NCA_SW "行车功能激活按键";
CM_ SG_ 1152 TBOX_PetmodeSetTemperature "宠物模式远程空调温度设置";
CM_ SG_ 1208 PPMID_1_PPMICounter "PPMI counter/寿命计数状态";
CM_ SG_ 1208 PPMID_1_PPMISt "PPMI status/ PPMI是否有故障";
CM_ SG_ 1208 PPMID_1_HWSts "Haptic Warning(HWA) /  震动触觉提醒";
CM_ SG_ 1208 PPMID_1_BSRBPASts "Belt slack reduction(BSR) / 织带间隙消除
Belt parking assist(BPA) / 织带辅助回收";
CM_ SG_ 794 ADS_3_ICAStatus "ICA状态信号";
CM_ SG_ 794 ADS_3_ICATextinfo "ICA状态信号（文本提示）";
CM_ SG_ 794 ADS_3_ACCSts "ACC状态信号";
CM_ SG_ 794 ADS_3_DriverHandsoffWarning "驾驶员脱手报警请求";
CM_ SG_ 794 ADS_3_LKSMod "LDW LDP激活模式状态";
CM_ SG_ 794 ADS_3_LKSSts "LKS状态信号";
CM_ SG_ 794 ADS_3_ELKSts "ELK状态信号";
CM_ SG_ 794 ADS_3_LKSLeftTrackingSt "LDW LDP左侧车道线激活状态";
CM_ SG_ 794 ADS_3_LKSRightTrackingSt "LDW LDP右侧车道线激活状态";
CM_ SG_ 794 ADS_3_ELKLeftActiveSt "ELK左侧车道线激活状态";
CM_ SG_ 794 ADS_3_ELKRightActiveSt "ELK右侧车道线激活状态";
CM_ SG_ 1155 ASU_3_horizontalSts "露营找平开关状态
0x1:ON开关开启
0x2:OFF开关关闭";
CM_ SG_ 1155 ASU_3_horizontalmodeFb "露营找平模式反馈
0x0:Not Active条件不满足，未激活
0x1:Working找平中
0x2:Complete找平完成
0x3:Abort找平中断
0x4:Failure找平失败";
CM_ SG_ 789 ATCM_DriveModeSw "驾驶模式状态
（正旋一次共发送4帧信号：
三帧0×1加一帧0×0
反旋一次共发送4帧信号：
三帧0×2加一帧0×0
信号周期20ms/帧）";
CM_ SG_ 789 ATCM_XModeSw "X模式状态";
CM_ SG_ 789 ATCM_SwitchUTurnModeSet "极限掉头开关/坦克掉头
（点击一次共发送3帧信号：
三帧0×1）";
CM_ SG_ 789 ATCM_ASU_LiftSet "悬架升高
（点击一次共发送3帧信号：
三帧0×1）";
CM_ SG_ 789 ATCM_ASU_LowerSet "悬架降低
（点击一次共发送3帧信号：
三帧0×1）";
CM_ SG_ 789 ATCM_ESP_OFF_SW "车身稳定控制系统关闭ESP—OFF开关
（点击一次共发送3帧信号：
三帧0×1）";
CM_ SG_ 789 ATCM_AVH_SW "自动驻车/AVH开关
（点击一次共发送3帧信号：
三帧0×1）";
CM_ SG_ 789 ATCM_AVM "AVM开关
（点击一次共发送3帧信号：
三帧0×1）";
CM_ SG_ 1214 BNCM_16_CRC1 "Profile1A:E2E CRC (SAE J1850 CRC-8) for 8 Bytes
DataID:No ASIL requirements.Not configure
CRC Reserved.";
CM_ SG_ 1214 BNCM_16_RollgCntr1 "Profile1A:E2E Rolling message counter(the maximum value of Alive counter is 14)要求启动计数，每发一帧计数一次，到最大值14之后从0重新计数，防止有两个连续单帧的情况发生";
CM_ SG_ 1214 BNCM_16_Resd1 "Profile1A:E2E Reserved";
CM_ SG_ 1095 RLCR_1_CRC1 "Profile1A:E2E CRC (SAE J1850 CRC-8) for 8 Bytes
DataID:0x0044";
CM_ SG_ 1095 RLCR_1_RollgCntr1 "Profile1A:E2E Rolling message counter(the maximum value of Alive counter is 14)";
CM_ SG_ 1095 RLCR_1_Resd1 "Profile1A:E2E Reserved";
CM_ SG_ 1095 RLCR_1_SysSt "System self-test State";
CM_ SG_ 1095 RLCR_1_BlkSts "Blockage Status";
CM_ SG_ 1095 RLCR_1_BSDWarn "BSD/LCA Warning";
CM_ SG_ 1095 RLCR_1_DOWWarn "Door open warning Warning";
CM_ SG_ 1095 RLCR_1_DowLock "Door locking Warning（功能预留不发）";
CM_ SG_ 1267 RRCR_1_CRC1 "Profile1A:E2E CRC (SAE J1850 CRC-8) for 8 Bytes
DataID:0x0046";
CM_ SG_ 1267 RRCR_1_RollgCntr1 "Profile1A:E2E Rolling message counter(the maximum value of Alive counter is 14)";
CM_ SG_ 1267 RRCR_1_Resd1 "Profile1A:E2E Reserved";
CM_ SG_ 1267 RRCR_1_SysSt "System self-test State";
CM_ SG_ 1267 RRCR_1_BlkSts "Blockage Status";
CM_ SG_ 1267 RRCR_1_BSDWarn "BSD/LCA Warning";
CM_ SG_ 1267 RRCR_1_DOWWarn "Door open warning Warning";
CM_ SG_ 1267 RRCR_1_DowLock "Door locking Warning（功能预留不发）";
CM_ SG_ 788 ADS_2_AEBStatus "AEB状态信号
以下为平台化库数据内容
0x0:OFF
0x1:ON
0x2:Failure
0x3:no_active(0x3:available捷途使用)
0x4:active
0x5:pre-fill
0x6 blindness(捷途使用)";
CM_ SG_ 788 ADS_2_FCWStatus "FCW状态信号";
CM_ SG_ 788 FCM_2_IHCfunctionSts "远近光自动切换功能状态";
CM_ SG_ 571 LHTurnlightSts "转向灯-左";
CM_ SG_ 571 RHTurnlightSts "转向灯-右";
CM_ SG_ 571 LHFDoorLockSts "主驾门锁";
CM_ SG_ 571 LHTurnSW "左转向开关，打开发1；关闭发0，默认发0";
CM_ SG_ 571 RHTurnSW "右转向开关，打开发1；关闭发0，默认发0";
CM_ SG_ 571 HazardLightSW "带自锁的开关，按照危险灯状态发送；不带自锁的开关，发送危险灯状态";
CM_ SG_ 571 LHFSeatBeltSW "安全带检测开关，0为未插入，1为插入";
CM_ SG_ 571 DirectionIndLeft "当左转向灯闪烁时一直发1，转向灯熄灭时一直发0.";
CM_ SG_ 571 DirectionIndRight "当右转向灯闪烁时一直发1，转向灯熄灭时一直发0.";
CM_ SG_ 699 LHRdoorSts "左后门状态";
CM_ SG_ 787 ChrgHoodSts "充电口盖状态反馈
股份FLZCU0x33E发，捷途由FRZCU发";
CM_ SG_ 787 FRZCU_FRSitPosnSts "副驾座椅记忆位置反馈";
CM_ SG_ 524 ADS_6_Customize_buttonsFB "自定义按键大屏设置设置项反馈
0x4:记忆泊车";
CM_ SG_ 572 ONEBOX_7_TAB_HighTemp "坦克转弯工作温度过高";
CM_ SG_ 572 ONEBOX_7_TAB_Active "IPB反馈TAB状态";
CM_ SG_ 572 ONEBOX_7_BSW_Active "智能擦盘状态反馈信号";
CM_ SG_ 572 ONEBOX_7_iCCO_TgtVel "iCCO功能目标车速";
CM_ SG_ 783 ADCC_SysReadySts "ADAS系统状态";
CM_ SG_ 943 CSA_3_CRC1 "Profile1A:E2E CRC (SAE J1850 CRC-8) for 8 Bytes
DataID:Reserved";
CM_ SG_ 943 CSA_3_RollgCntr1 "Profile1A:E2E Rolling message counter(the maximum value of Alive counter is 14)";
CM_ SG_ 943 CSA_3_Resd1 "Profile1A:E2E Reserved";
CM_ SG_ 943 FlwheelBearing "持续发送左前轮载荷值(吨)";
CM_ SG_ 943 FrwheelBearing "持续发送右前轮载荷值(吨)";
CM_ SG_ 943 BlwheelBearing "持续发送左后轮载荷值(吨)";
CM_ SG_ 943 BrwheelBearing "持续发送右后轮载荷值(吨)";
CM_ SG_ 943 CSA_3_CRC2 "Profile1A:E2E CRC (SAE J1850 CRC-8) for 8 Bytes
DataID:Reserved";
CM_ SG_ 943 CSA_3_RollgCntr2 "Profile1A:E2E Rolling message counter(the maximum value of Alive counter is 14)";
CM_ SG_ 943 VehicleBearing_kg "持续发送整车重量(kg)";
CM_ SG_ 943 VehicleBearing_lb "持续发送整车重量(lb)";
CM_ SG_ 943 GoodsWeight_kg "持续发送货物重量(kg)";
CM_ SG_ 943 Goods_Weight_Ratio "持续发送货物重量百分比(%)";
CM_ SG_ 943 CSA_3_CRC3 "Profile1A:E2E CRC (SAE J1850 CRC-8) for 8 Bytes
DataID:Reserved";
CM_ SG_ 943 CSA_3_RollgCntr3 "Profile1A:E2E Rolling message counter(the maximum value of Alive counter is 14)";
CM_ SG_ 943 CSA_3_Resd3 "Profile1A:E2E Reserved";
CM_ SG_ 943 GoodsWeight_lb "持续发送货物重量(lb)";
CM_ SG_ 943 OverWeightValue_kg "持续发送超重值（kg)";
CM_ SG_ 943 OverWeightValue_lb "持续发送超重值（lb)";
CM_ SG_ 943 OverWeightRatio "持续发送超重百公比(%)";
CM_ SG_ 943 OverWeightWarning "超重时发送超重报警信号";
CM_ SG_ 943 OverLoadWarnShieldSetFed "大屏重量报警屏蔽软开关反馈信号";
CM_ SG_ 943 Fraxlebearingrate "前后轴偏置百分比";
CM_ SG_ 1120 RLHS_2_AmbBrightness "顶向光";
CM_ SG_ 1120 RLHS_LiSwithReason "开关灯切换原因
RLS_ LightSwithReason";
CM_ SG_ 850 ASU_6_HMIFailFb_JT "0x0:无状态，不显示
0x1:悬架调节已锁定，请先解除锁定
0x2:尾门未关闭，载物模式已退出
0x3:悬架高度调节已禁用
0x4:悬架软硬调节已禁用
0x5:当前海拔过高，悬架高度调节已禁用
0x6:仪表弹窗提醒:供气单元使用超时,请稍后重试!
0x7:仪表弹窗提醒:供气单元工作异常,请前往服务站检修!
0x8:越野穿越条件不满足，请确认后重试
0x9:越野穿越已退出
0xA:补气条件不满足，请确认条件后重试
0xB:地库模式进入条件不满足，请确认后重试
0xC:地库模式已退出
0xD~0xF:reserved";
CM_ SG_ 850 ASU_inflate_352h "空簧一键充气功能开关状态反馈";
CM_ SG_ 850 ASU_trekthrough_352h "空簧越野穿越开关状态反馈";
CM_ SG_ 850 ASU_undergroundmode_352h "空簧地库模式开关状态反馈";
CM_ SG_ 1199 TCM_1_TrailerSts "Trailer Status send by TCM. Vehicle can use this information to turn off/on some assistance like Park Distance Control. Furthermore it might be used to turn off the fog light on the vehicle when a trailer is connected (at least in germany, there is a law saying that the vehicles fog lamp must not be turned on when a trailer is connected - only the fog of the trailer should be turned on).";
CM_ SG_ 1131 ClutchTemperature_46Bh "Clutch temperature
离合器温度";
CM_ SG_ 1131 GBFaultstatus_46Bh "Activation gearbox error Lamp, only for ICM including LCD to light LED and LCD. This signal should be sent with “AGErrorLamp” simultaneously
For 6DCT,only has 00/01.
For CVT/AMT/AT, only has 00/01/10.
变速箱故障状态";
CM_ SG_ 1131 GBPositoionDisplay_46Bh "gear box positoion Display
挡位显示给仪表";
CM_ SG_ 1060 InforDisplay_424h "误操作提示信号";
CM_ SG_ 1129 EngineCoolantTemp_469h "Engine Coolant Temperture发动机冷却液温度";
CM_ SG_ 1129 EngineSpeed_469h "Engine Speed发动机转速";
CM_ SG_ 1129 EngineSpeedValidData_469h "Valid check bit of the signal EngineSpeed发动机转速有效位";
CM_ SG_ 1128 PromptMesg_468h "PromptMessage真空泵消息提示信号

当ICM接收到0x01时，仪表盘提示:“真空泵测试无法完成，请松开脚刹。”";
CM_ SG_ 1018 FLZCU_KeyDriveModememory_3FAh "驾驶模式记忆开关反馈";
CM_ SG_ 1018 FLZCU_DriveModeChangeFail_3FAh "驾驶模式切换不满足条件，提示“请停车后退出当前驾驶模式”";
CM_ SG_ 1018 FLZCU_DraggingModeRemind_3FAh "拖挂模式功能提示
0x0: 无提示
0x1:禁用ECO和越野模式
0x2:拖挂模式下仅支持Normal和Sport
0x3:ECO和越野模式恢复
0x4~0x7：预留";
CM_ SG_ 1018 FLZCU_CCOSwtFed_3FAh "越野蠕行开关反馈";
CM_ SG_ 1018 FLZCU_CCO_TextDisp_3FAh "CCO功能提示信息
越野蠕行功能提示";
CM_ SG_ 1018 FLZCU_DriveMode_3FAh "驾驶模式状态信号（显示）
捷途新增0xD:X模式";
CM_ SG_ 1123 ISS_Switch_Sts_463h "Start-stop switch state feedback signal 启停开关状态反馈";
BA_DEF_ BO_  "GenMsgCycleTimeFast" INT 0 50000;
BA_DEF_ BO_  "GenMsgNrOfRepetition" INT 0 999999;
BA_DEF_ BO_  "GenMsgDelayTime" INT 0 1000;
BA_DEF_ BO_  "VFrameFormat" ENUM  "StandardCAN","ExtendedCAN","reserved","reserved","reserved","reserved","reserved","reserved","reserved","reserved","reserved","reserved","reserved","reserved","StandardCAN_FD","ExtendedCAN_FD";
BA_DEF_ BO_  "GenMsgILSupport" ENUM  "No","Yes";
BA_DEF_ BO_  "NmMessage" ENUM  "No","Yes";
BA_DEF_ BO_  "DiagMessage" ENUM  "No","Yes";
BA_DEF_ BO_  "GenMsgSendType" ENUM  "Cyclic","Event","IfActive","CE","CA","NoMsgSendType";
BA_DEF_ BO_  "GenMsgCycleTime" INT 0 50000;
BA_DEF_ BO_  "CANFD_BRS" INT 0 1;
BA_DEF_ BO_  "NmAsrMessage" ENUM  "No","Yes";
BA_DEF_ BO_  "DiagState" ENUM  "No","Yes";
BA_DEF_ BO_  "DiagRequest" ENUM  "No","Yes";
BA_DEF_ BO_  "DiagResponse" ENUM  "No","Yes";
BA_DEF_ BO_  "MsgType" ENUM  "IL","NM","DIAG","APPL";
BA_DEF_ BO_  "Msg_ASIL" ENUM  "vector_leerstring","QM","A","B","C","D";
BA_DEF_ BO_  "GRC_History" STRING ;
BA_DEF_ SG_  "GenSigStartValue" FLOAT 0 100000000000;
BA_DEF_ SG_  "GenSigInactiveValue" INT 0 100000;
BA_DEF_ SG_  "GenSigInvalidValue" INT 0 100000;
BA_DEF_ SG_  "GenSigSendType" ENUM  "Cyclic","OnChange","OnWrite","IfActive","OnChangeWithRepetition","OnWriteWithRepetition","IfActiveWithRepetition","NoSigSendType","OnChangeAndIfActive","OnChangeAndIfActiveWithRepetition","CA","CE","Event";
BA_DEF_ SG_  "ASIL" ENUM  "vector_leerstring","QM","A","B","C","D";
BA_DEF_DEF_  "GenMsgCycleTimeFast" 0;
BA_DEF_DEF_  "GenMsgNrOfRepetition" 0;
BA_DEF_DEF_  "GenMsgDelayTime" 0;
BA_DEF_DEF_  "VFrameFormat" "StandardCAN";
BA_DEF_DEF_  "GenMsgILSupport" "No";
BA_DEF_DEF_  "NmMessage" "No";
BA_DEF_DEF_  "DiagMessage" "No";
BA_DEF_DEF_  "GenMsgSendType" "NoMsgSendType";
BA_DEF_DEF_  "GenMsgCycleTime" 0;
BA_DEF_DEF_  "CANFD_BRS" 0;
BA_DEF_DEF_  "NmAsrMessage" "No";
BA_DEF_DEF_  "DiagState" "No";
BA_DEF_DEF_  "DiagRequest" "No";
BA_DEF_DEF_  "DiagResponse" "No";
BA_DEF_DEF_  "MsgType" "";
BA_DEF_DEF_  "Msg_ASIL" "";
BA_DEF_DEF_  "GRC_History" "";
BA_DEF_DEF_  "GenSigStartValue" 0;
BA_DEF_DEF_  "GenSigInactiveValue" 0;
BA_DEF_DEF_  "GenSigInvalidValue" 0;
BA_DEF_DEF_  "GenSigSendType" "NoSigSendType";
BA_DEF_DEF_  "ASIL" "";
BA_ "GenMsgILSupport" BO_ 819 1;
BA_ "MsgType" BO_ 819 0;
BA_ "GenMsgCycleTime" BO_ 819 50;
BA_ "GenMsgSendType" BO_ 819 0;
BA_ "CANFD_BRS" BO_ 819 1;
BA_ "VFrameFormat" BO_ 819 14;
BA_ "GenMsgILSupport" BO_ 1172 1;
BA_ "MsgType" BO_ 1172 0;
BA_ "GenMsgCycleTime" BO_ 1172 100;
BA_ "GenMsgSendType" BO_ 1172 0;
BA_ "CANFD_BRS" BO_ 1172 1;
BA_ "VFrameFormat" BO_ 1172 14;
BA_ "GRC_History" BO_ 1147 "[{'approvedBy':'贾少辉','author':'吴俊祥','changesComments':'根据与热管理FLCCP杨洋、AIPM齐静沟通确认\n1、将报文行信号描述列备注删除\n2、CCP_1_FLTempSwitchReq信号描述更新为“前排左侧温度调节”，GL网段无接收端','date':'2026/1/7','ecu':'CCP_1（0x47B）','ecu";
BA_ "GenMsgILSupport" BO_ 1147 1;
BA_ "MsgType" BO_ 1147 0;
BA_ "GenMsgDelayTime" BO_ 1147 5;
BA_ "GenMsgNrOfRepetition" BO_ 1147 3;
BA_ "GenMsgCycleTimeFast" BO_ 1147 20;
BA_ "GenMsgCycleTime" BO_ 1147 100;
BA_ "GenMsgSendType" BO_ 1147 3;
BA_ "CANFD_BRS" BO_ 1147 1;
BA_ "VFrameFormat" BO_ 1147 14;
BA_ "GenMsgILSupport" BO_ 1107 1;
BA_ "MsgType" BO_ 1107 0;
BA_ "GenMsgCycleTime" BO_ 1107 100;
BA_ "GenMsgSendType" BO_ 1107 0;
BA_ "CANFD_BRS" BO_ 1107 1;
BA_ "VFrameFormat" BO_ 1107 14;
BA_ "GRC_History" BO_ 1175 "[{'approvedBy':'贾少辉','author':'吴俊祥','changesComments':'根据与热管理FRCCP杨洋、AIPM齐静沟通确认\nCCP_2_FRTempSwitchReq信号描述更新为“前排右侧温度调节”','date':'2026/1/7','ecu':'CCP_2（0x497）','ecuName':'ICC,ICC_ICE,CGW','reviewedBy':'杨华','revis";
BA_ "GenMsgILSupport" BO_ 1175 1;
BA_ "MsgType" BO_ 1175 0;
BA_ "GenMsgDelayTime" BO_ 1175 5;
BA_ "GenMsgNrOfRepetition" BO_ 1175 3;
BA_ "GenMsgCycleTimeFast" BO_ 1175 20;
BA_ "GenMsgCycleTime" BO_ 1175 100;
BA_ "GenMsgSendType" BO_ 1175 3;
BA_ "CANFD_BRS" BO_ 1175 1;
BA_ "VFrameFormat" BO_ 1175 14;
BA_ "GenMsgILSupport" BO_ 1292 1;
BA_ "MsgType" BO_ 1292 0;
BA_ "GenMsgCycleTime" BO_ 1292 500;
BA_ "GenMsgSendType" BO_ 1292 0;
BA_ "CANFD_BRS" BO_ 1292 1;
BA_ "VFrameFormat" BO_ 1292 14;
BA_ "GenMsgILSupport" BO_ 49 1;
BA_ "MsgType" BO_ 49 0;
BA_ "GenMsgCycleTime" BO_ 49 10;
BA_ "GenMsgSendType" BO_ 49 0;
BA_ "CANFD_BRS" BO_ 49 1;
BA_ "VFrameFormat" BO_ 49 14;
BA_ "GRC_History" BO_ 1024 "[{'approvedBy':'贾少辉','author':'吴俊祥','changesComments':'同步需求\n根据电子电器FRZCU丁阁文、徐治武需求（执行BNCM远离闭锁时，遥控钥匙在车内手机提醒）\n新增信号PEPS_BNCMWALInKeyWarning,给BNCM收','date':'2025/9/1','ecu':'FRZCU_13(0x400)','ecuName':'CGW'";
BA_ "GenMsgILSupport" BO_ 1024 1;
BA_ "MsgType" BO_ 1024 0;
BA_ "GenMsgCycleTime" BO_ 1024 100;
BA_ "GenMsgSendType" BO_ 1024 0;
BA_ "CANFD_BRS" BO_ 1024 1;
BA_ "VFrameFormat" BO_ 1024 14;
BA_ "GenMsgILSupport" BO_ 290 1;
BA_ "MsgType" BO_ 290 0;
BA_ "GenMsgCycleTime" BO_ 290 10;
BA_ "GenMsgSendType" BO_ 290 0;
BA_ "CANFD_BRS" BO_ 290 1;
BA_ "VFrameFormat" BO_ 290 14;
BA_ "GRC_History" BO_ 513 "[{'approvedBy':'贾少辉','author':'吴俊祥','changesComments':'同步T1J 华为信号：\n新增信号MFSL_APA_SW、MFSL_LCC_NCA_SW','date':'2025/9/22','ecu':'MFSL_1（0x201)','ecuName':'ICC','reviewedBy':'杨华','revision':'V1.2'}]";
BA_ "GenMsgILSupport" BO_ 513 1;
BA_ "MsgType" BO_ 513 0;
BA_ "GenMsgCycleTime" BO_ 513 20;
BA_ "GenMsgSendType" BO_ 513 0;
BA_ "CANFD_BRS" BO_ 513 1;
BA_ "VFrameFormat" BO_ 513 14;
BA_ "GRC_History" BO_ 1152 "[{'approvedBy':'贾少辉','author':'吴俊祥','changesComments':'已与TBOX沟通确认，电子电器FRZCU丁阁文、郑涵文，TMS陶振宇、魏成贤同步沟通\n这2个信号TBOX_IONWorkReq、TBOX_UVCControlReq发送类型由Event更新为OnWriteWithRepetition','date':'2025/9/10','ecu':'TBOX_";
BA_ "GenMsgILSupport" BO_ 1152 1;
BA_ "MsgType" BO_ 1152 0;
BA_ "GenMsgDelayTime" BO_ 1152 5;
BA_ "GenMsgNrOfRepetition" BO_ 1152 3;
BA_ "GenMsgCycleTimeFast" BO_ 1152 100;
BA_ "GenMsgSendType" BO_ 1152 1;
BA_ "CANFD_BRS" BO_ 1152 1;
BA_ "VFrameFormat" BO_ 1152 14;
BA_ "GenMsgILSupport" BO_ 1208 1;
BA_ "MsgType" BO_ 1208 0;
BA_ "GenMsgCycleTime" BO_ 1208 100;
BA_ "GenMsgSendType" BO_ 1208 0;
BA_ "CANFD_BRS" BO_ 1208 1;
BA_ "VFrameFormat" BO_ 1208 14;
BA_ "GenMsgILSupport" BO_ 794 1;
BA_ "MsgType" BO_ 794 0;
BA_ "GenMsgCycleTime" BO_ 794 50;
BA_ "GenMsgSendType" BO_ 794 0;
BA_ "CANFD_BRS" BO_ 794 1;
BA_ "VFrameFormat" BO_ 794 14;
BA_ "GenMsgILSupport" BO_ 1155 1;
BA_ "MsgType" BO_ 1155 0;
BA_ "GenMsgCycleTime" BO_ 1155 100;
BA_ "GenMsgSendType" BO_ 1155 0;
BA_ "CANFD_BRS" BO_ 1155 1;
BA_ "VFrameFormat" BO_ 1155 14;
BA_ "GRC_History" BO_ 789 "[{'approvedBy':'贾少辉','author':'吴俊祥','changesComments':'OA：JTPPSYB-QT-2025-87877号&JTPPSYB-QT-2025-87514号\nATCM_ASU_LiftSet和ATCM_ASU_LowerSet信号新增ICC接收——汪振生、张海源','date':'2025/8/26','ecu':'ATCM_1(0x315)','ecuName':'ICC','reviewedBy':";
BA_ "GenMsgILSupport" BO_ 789 1;
BA_ "MsgType" BO_ 789 0;
BA_ "GenMsgDelayTime" BO_ 789 5;
BA_ "GenMsgNrOfRepetition" BO_ 789 3;
BA_ "GenMsgCycleTimeFast" BO_ 789 20;
BA_ "GenMsgSendType" BO_ 789 1;
BA_ "CANFD_BRS" BO_ 789 1;
BA_ "VFrameFormat" BO_ 789 14;
BA_ "GenMsgILSupport" BO_ 1214 1;
BA_ "MsgType" BO_ 1214 0;
BA_ "GenMsgDelayTime" BO_ 1214 5;
BA_ "GenMsgSendType" BO_ 1214 1;
BA_ "CANFD_BRS" BO_ 1214 1;
BA_ "VFrameFormat" BO_ 1214 14;
BA_ "GenMsgILSupport" BO_ 1095 1;
BA_ "MsgType" BO_ 1095 0;
BA_ "GenMsgCycleTime" BO_ 1095 100;
BA_ "GenMsgSendType" BO_ 1095 0;
BA_ "CANFD_BRS" BO_ 1095 1;
BA_ "VFrameFormat" BO_ 1095 14;
BA_ "GenMsgILSupport" BO_ 1267 1;
BA_ "MsgType" BO_ 1267 0;
BA_ "GenMsgCycleTime" BO_ 1267 100;
BA_ "GenMsgSendType" BO_ 1267 0;
BA_ "CANFD_BRS" BO_ 1267 1;
BA_ "VFrameFormat" BO_ 1267 14;
BA_ "GRC_History" BO_ 788 "[{'approvedBy':'贾少辉','author':'吴俊祥','changesComments':'流水号:JTPPSYB-BG-2026-02932号：\n1、新增SentinelModeSwitchSts_314h、SentinelModeSensitivitySts_314h、SentinelModeSts_314h、SentinelModeWorkingSts_314h、SentinelModeAlarmSts_314h、SentinelModeE";
BA_ "GenMsgILSupport" BO_ 788 1;
BA_ "MsgType" BO_ 788 0;
BA_ "GenMsgCycleTime" BO_ 788 50;
BA_ "GenMsgSendType" BO_ 788 0;
BA_ "CANFD_BRS" BO_ 788 1;
BA_ "VFrameFormat" BO_ 788 14;
BA_ "GRC_History" BO_ 571 "[{'approvedBy':'贾少辉','author':'吴俊祥','changesComments':'同步T1J 华为信号：\n新增信号LHFdoorSts_Valid（bit47）—郑涵文','date':'2025/9/22','ecu':'FLZCU_1(0x23B)','ecuName':'FLZCU','reviewedBy':'杨华','revision':'V1.2'},{'approvedBy':'贾少辉','author'";
BA_ "GenMsgILSupport" BO_ 571 1;
BA_ "MsgType" BO_ 571 0;
BA_ "GenMsgCycleTime" BO_ 571 20;
BA_ "GenMsgSendType" BO_ 571 0;
BA_ "CANFD_BRS" BO_ 571 1;
BA_ "VFrameFormat" BO_ 571 14;
BA_ "GRC_History" BO_ 699 "[{'approvedBy':'贾少辉','author':'吴俊祥','changesComments':'同步T1J 华为信号：\n新增信号LHRdoorSts_Valid（bit47）—郑涵文','date':'2025/9/22','ecu':'RZCU_2(0x2BB)','ecuName':'FLZCU','reviewedBy':'杨华','revision':'V1.2'}]";
BA_ "GenMsgILSupport" BO_ 699 1;
BA_ "MsgType" BO_ 699 0;
BA_ "GenMsgCycleTime" BO_ 699 20;
BA_ "GenMsgSendType" BO_ 699 0;
BA_ "CANFD_BRS" BO_ 699 1;
BA_ "VFrameFormat" BO_ 699 14;
BA_ "GRC_History" BO_ 787 "[{'approvedBy':'贾少辉','author':'吴俊祥','changesComments':'D01华为智驾版更新，电子电器FRZCU丁阁文需求\nFRZCU_PwrOnReason信号值描述增加0xD:ADS_Request','date':'2025/12/18','ecu':'FRZCU_14（0x313）','ecuName':'CGW','reviewedBy':'杨华','revision':'V1.4'},";
BA_ "Msg_ASIL" BO_ 787 3;
BA_ "GenMsgILSupport" BO_ 787 1;
BA_ "MsgType" BO_ 787 0;
BA_ "GenMsgCycleTime" BO_ 787 50;
BA_ "GenMsgSendType" BO_ 787 0;
BA_ "CANFD_BRS" BO_ 787 1;
BA_ "VFrameFormat" BO_ 787 14;
BA_ "GRC_History" BO_ 524 "[{'approvedBy':'贾少辉','author':'吴俊祥','changesComments':'新增：\n流水号:JTPPSYB-BG-2026-02932号\n1、新增“ADCC_SpeakerReq_20Ch；ADCC_HazardLightReq_20Ch”，ADCC发。[智舱部-夏超超][智驾部-张龙]','date':'2026/1/21','ecu':'ADS_6(0x20C)','ecuName':'CGW',";
BA_ "GenMsgILSupport" BO_ 524 1;
BA_ "MsgType" BO_ 524 0;
BA_ "GenMsgCycleTime" BO_ 524 20;
BA_ "GenMsgSendType" BO_ 524 0;
BA_ "CANFD_BRS" BO_ 524 1;
BA_ "VFrameFormat" BO_ 524 14;
BA_ "GRC_History" BO_ 572 "[{'approvedBy':'贾少辉','author':'吴俊祥','changesComments':'修改：\n1、流水号:JTPPSYB-QT-2025-116206号，“ONEBOX_7_BSW_Active”修改0x3:Reserved->0x3:initialize。[底盘部-计尧]','date':'2025/11/18','ecu':'ONEBOX_7(0x23C)','ecuName':'ICC,CGW','reviewedBy':";
BA_ "GenMsgILSupport" BO_ 572 1;
BA_ "MsgType" BO_ 572 0;
BA_ "GenMsgCycleTime" BO_ 572 20;
BA_ "GenMsgSendType" BO_ 572 0;
BA_ "CANFD_BRS" BO_ 572 1;
BA_ "VFrameFormat" BO_ 572 14;
BA_ "GenMsgILSupport" BO_ 783 1;
BA_ "MsgType" BO_ 783 0;
BA_ "GenMsgCycleTime" BO_ 783 50;
BA_ "GenMsgSendType" BO_ 783 0;
BA_ "CANFD_BRS" BO_ 783 1;
BA_ "VFrameFormat" BO_ 783 14;
BA_ "GenMsgILSupport" BO_ 1110 1;
BA_ "MsgType" BO_ 1110 0;
BA_ "GenMsgSendType" BO_ 1110 1;
BA_ "CANFD_BRS" BO_ 1110 1;
BA_ "VFrameFormat" BO_ 1110 14;
BA_ "GenMsgILSupport" BO_ 1149 1;
BA_ "MsgType" BO_ 1149 0;
BA_ "GenMsgSendType" BO_ 1149 1;
BA_ "CANFD_BRS" BO_ 1149 1;
BA_ "VFrameFormat" BO_ 1149 14;
BA_ "GenMsgILSupport" BO_ 1037 1;
BA_ "MsgType" BO_ 1037 0;
BA_ "GenMsgCycleTime" BO_ 1037 100;
BA_ "GenMsgSendType" BO_ 1037 0;
BA_ "CANFD_BRS" BO_ 1037 1;
BA_ "VFrameFormat" BO_ 1037 14;
BA_ "GenMsgILSupport" BO_ 943 1;
BA_ "MsgType" BO_ 943 0;
BA_ "GenMsgCycleTime" BO_ 943 50;
BA_ "GenMsgSendType" BO_ 943 0;
BA_ "CANFD_BRS" BO_ 943 1;
BA_ "VFrameFormat" BO_ 943 14;
BA_ "GenMsgILSupport" BO_ 1120 1;
BA_ "MsgType" BO_ 1120 0;
BA_ "GenMsgCycleTime" BO_ 1120 100;
BA_ "GenMsgSendType" BO_ 1120 0;
BA_ "CANFD_BRS" BO_ 1120 1;
BA_ "VFrameFormat" BO_ 1120 14;
BA_ "GRC_History" BO_ 850 "[{'approvedBy':'贾少辉','author':'吴俊祥','changesComments':'同步D01\n修改：\n流水号:JTPPSYB-QT-2025-127935号\n1、“ASU_6_HMIFailFb_JT”修改枚举值为“0x0:Not Active\n0x0:Not_Active\n0x1:SUSP_IS_lock\n0x2:PLG_is_open\n0x3:suspension_height_disable\n0x4:su";
BA_ "GenMsgILSupport" BO_ 850 1;
BA_ "MsgType" BO_ 850 0;
BA_ "GenMsgCycleTime" BO_ 850 50;
BA_ "GenMsgSendType" BO_ 850 0;
BA_ "CANFD_BRS" BO_ 850 1;
BA_ "VFrameFormat" BO_ 850 14;
BA_ "Msg_ASIL" BO_ 1199 3;
BA_ "GenMsgILSupport" BO_ 1199 1;
BA_ "MsgType" BO_ 1199 0;
BA_ "GenMsgCycleTime" BO_ 1199 100;
BA_ "GenMsgSendType" BO_ 1199 0;
BA_ "CANFD_BRS" BO_ 1199 1;
BA_ "VFrameFormat" BO_ 1199 14;
BA_ "GRC_History" BO_ 1131 "[{'approvedBy':'贾少辉','author':'吴俊祥','changesComments':'T1J FL3 燃油需求：\n新增报文0x46B报文：\nClutchTemperature_46Bh、GBFaultstatus_46Bh、GBPositoionDisplay_46Bh新增ICC_ICE接收','date':'2025/10/13','ecu':'TCU_46Bh(0x46B)','ecuName':'CGW,ICC_ICE',";
BA_ "GenMsgILSupport" BO_ 1131 1;
BA_ "MsgType" BO_ 1131 0;
BA_ "GenMsgCycleTime" BO_ 1131 100;
BA_ "GenMsgSendType" BO_ 1131 0;
BA_ "CANFD_BRS" BO_ 1131 1;
BA_ "VFrameFormat" BO_ 1131 14;
BA_ "GRC_History" BO_ 1060 "[{'approvedBy':'贾少辉','author':'吴俊祥','changesComments':'T1J FL3 燃油需求：\n新增报文0x424报文：\nInforDisplay_424h新增ICC_ICE接收','date':'2025/10/13','ecu':'TCU_424h(0x424)','ecuName':'CGW,ICC_ICE','reviewedBy':'杨华','revision':'V1.2'}]";
BA_ "GenMsgILSupport" BO_ 1060 1;
BA_ "MsgType" BO_ 1060 0;
BA_ "GenMsgCycleTime" BO_ 1060 100;
BA_ "GenMsgSendType" BO_ 1060 0;
BA_ "CANFD_BRS" BO_ 1060 1;
BA_ "VFrameFormat" BO_ 1060 14;
BA_ "GRC_History" BO_ 1129 "[{'approvedBy':'贾少辉','author':'吴俊祥','changesComments':'T1J FL3 燃油需求：\n新增报文0x469报文：\nEngineSpeed_469h、EngineSpeedValidData_469h新增ICC_ICE接收','date':'2025/10/13','ecu':'EMS_COM_469h(0x469)','ecuName':'CGW,ICC_ICE','reviewedBy':'杨华',";
BA_ "GenMsgILSupport" BO_ 1129 1;
BA_ "MsgType" BO_ 1129 0;
BA_ "GenMsgCycleTime" BO_ 1129 100;
BA_ "GenMsgSendType" BO_ 1129 0;
BA_ "CANFD_BRS" BO_ 1129 1;
BA_ "VFrameFormat" BO_ 1129 14;
BA_ "GRC_History" BO_ 1128 "[{'approvedBy':'贾少辉','author':'吴俊祥','changesComments':'T1J FL3 燃油需求：\n新增报文0x468报文：\nPromptMesg_468h新增ICC_ICE接收','date':'2025/10/13','ecu':'EMS_ICC_468h(0x468)','ecuName':'CGW,ICC_ICE','reviewedBy':'杨华','revision':'V1.2'}]";
BA_ "GenMsgILSupport" BO_ 1128 1;
BA_ "MsgType" BO_ 1128 0;
BA_ "GenMsgCycleTime" BO_ 1128 100;
BA_ "GenMsgSendType" BO_ 1128 0;
BA_ "CANFD_BRS" BO_ 1128 1;
BA_ "VFrameFormat" BO_ 1128 14;
BA_ "GRC_History" BO_ 1018 "[{'approvedBy':'贾少辉','author':'吴俊祥','changesComments':'新增报文0x3FA，FLZCU_KeyDriveModememory_3FAh、FLZCU_DriveModeChangeFail_3FAh、FLZCU_DraggingModeRemind_3FAh、FLZCU_CCOSwtFed_3FAh、FLZCU_CCO_TextDisp_3FAh、FLZCU_DriveMode_3FAh信号ICC接收，用于";
BA_ "GenMsgILSupport" BO_ 1018 1;
BA_ "MsgType" BO_ 1018 0;
BA_ "GenMsgCycleTime" BO_ 1018 100;
BA_ "GenMsgSendType" BO_ 1018 0;
BA_ "CANFD_BRS" BO_ 1018 1;
BA_ "VFrameFormat" BO_ 1018 14;
BA_ "GRC_History" BO_ 1123 "[{'approvedBy':'贾少辉','author':'吴俊祥','changesComments':'燃油EMS启停功能：\n新增转发报文，并增加ISS_Switch_Sts_463h信号ICC_ICE接收-[智舱部-姜新]','date':'2026/2/3','ecu':'EMS_463h(0x463)','ecuName':'ICC_ICE','reviewedBy':'杨华','revision':'V1.5'}]";
BA_ "GenMsgILSupport" BO_ 1123 1;
BA_ "MsgType" BO_ 1123 0;
BA_ "GenMsgCycleTime" BO_ 1123 100;
BA_ "GenMsgSendType" BO_ 1123 0;
BA_ "CANFD_BRS" BO_ 1123 1;
BA_ "VFrameFormat" BO_ 1123 14;
BA_ "GRC_History" BO_ 1972 "[{'approvedBy':'贾少辉','author':'吴俊祥','changesComments':'新增FLZCU诊断响应报文，用于ICC OTA功能','date':'2025/12/22','ecu':'Diag_FLZCU_RES(0x7B4)','ecuName':'ICC,ICC_ICE,FLZCU','reviewedBy':'杨华','revision':'V1.4'}]";
BA_ "DiagResponse" BO_ 1972 1;
BA_ "DiagMessage" BO_ 1972 1;
BA_ "MsgType" BO_ 1972 2;
BA_ "GenMsgSendType" BO_ 1972 1;
BA_ "CANFD_BRS" BO_ 1972 1;
BA_ "VFrameFormat" BO_ 1972 14;
BA_ "GRC_History" BO_ 1844 "[{'approvedBy':'贾少辉','author':'吴俊祥','changesComments':'新增FLZCU诊断请求报文，用于ICC OTA功能','date':'2025/12/22','ecu':'Diag_FLZCU_REQ(0x734)','ecuName':'ICC,ICC_ICE,FLZCU','reviewedBy':'杨华','revision':'V1.4'}]";
BA_ "DiagRequest" BO_ 1844 1;
BA_ "DiagMessage" BO_ 1844 1;
BA_ "MsgType" BO_ 1844 2;
BA_ "GenMsgSendType" BO_ 1844 1;
BA_ "CANFD_BRS" BO_ 1844 1;
BA_ "VFrameFormat" BO_ 1844 14;
BA_ "GenSigSendType" SG_ 819 ADS_4_CRC1 0;
BA_ "GenSigSendType" SG_ 819 ADS_4_RollgCntr1 0;
BA_ "GenSigSendType" SG_ 819 ADS_4_Resd1 0;
BA_ "GenSigSendType" SG_ 819 ADS_4_AEBStatus 0;
BA_ "GenSigSendType" SG_ 819 ADS_4_ACCSts 0;
BA_ "GenSigSendType" SG_ 819 ADS_4_TimeGapSet 0;
BA_ "GenSigSendType" SG_ 819 ADS_4_FcwMode 0;
BA_ "GenSigSendType" SG_ 819 ADS_4_AEBReqType 0;
BA_ "GenSigSendType" SG_ 819 ADS_4_SetSpd 0;
BA_ "GenSigSendType" SG_ 819 ADS_4_DAIStatus 0;
BA_ "GenSigSendType" SG_ 819 ADS_4_ACCTextMessage 0;
BA_ "GenSigSendType" SG_ 819 ADS_4_LongiTakeOverReq 0;
BA_ "GenSigSendType" SG_ 819 ADS_4_SetSpdUnit 0;
BA_ "GenSigSendType" SG_ 819 ADS_4_GoNotifier 0;
BA_ "GenSigSendType" SG_ 819 ADS_4_DAISts 0;
BA_ "GenSigSendType" SG_ 819 ADS_4_Radar_textinfo 0;
BA_ "GenSigSendType" SG_ 819 ADS_4_SCF_PopoverReq 0;
BA_ "GenSigSendType" SG_ 819 ADS_4_DrvrCfmSCFDispFb 0;
BA_ "GenSigSendType" SG_ 819 ADS_4_SCF_SpdLimUnit 0;
BA_ "GenSigSendType" SG_ 819 ADS_4_SCF_SpdLimSts 0;
BA_ "GenSigSendType" SG_ 819 ADS_4_CRC2 0;
BA_ "GenSigSendType" SG_ 819 ADS_4_RollgCntr2 0;
BA_ "GenSigSendType" SG_ 819 ADS_4_Resd2 0;
BA_ "GenSigSendType" SG_ 819 ADS_4_ACCObjTyp 0;
BA_ "GenSigSendType" SG_ 819 ADS_4_FrntFarObjTyp 0;
BA_ "GenSigSendType" SG_ 819 ADS_4_ACCObjLgtDstX 0;
BA_ "GenSigSendType" SG_ 819 ADS_4_FrntFarObjID 0;
BA_ "GenSigSendType" SG_ 819 ADS_4_Resd 0;
BA_ "GenSigSendType" SG_ 819 ADS_4_ACCObjID 0;
BA_ "GenSigSendType" SG_ 819 ADS_4_ACCObjHozDstY 0;
BA_ "GenSigSendType" SG_ 819 ADS_4_FrntFarObjHozDstY 0;
BA_ "GenSigSendType" SG_ 819 ADS_4_FrntFarObjLgtDstX 0;
BA_ "GenSigSendType" SG_ 819 ADS_4_CRC3 0;
BA_ "GenSigSendType" SG_ 819 ADS_4_RollgCntr3 0;
BA_ "GenSigSendType" SG_ 819 ADS_4_Resd3 0;
BA_ "GenSigSendType" SG_ 819 ADS_4_Resd_1 0;
BA_ "GenSigSendType" SG_ 819 ADS_4_LeObjID 0;
BA_ "GenSigSendType" SG_ 819 ADS_4_LeObjTyp 0;
BA_ "GenSigSendType" SG_ 819 ADS_4_LeObjHozDstY 0;
BA_ "GenSigSendType" SG_ 819 ADS_4_LeObjLgtDstX 0;
BA_ "GenSigSendType" SG_ 819 ADS_4_RiObjID 0;
BA_ "GenSigSendType" SG_ 819 ADS_4_RiObjTyp 0;
BA_ "GenSigSendType" SG_ 819 ADS_4_RiObjHozDstY 0;
BA_ "GenSigSendType" SG_ 819 ADS_4_RiObjLgtDstX 0;
BA_ "GenSigSendType" SG_ 819 ADS_4_CRC4 0;
BA_ "GenSigSendType" SG_ 819 ADS_4_RollgCntr4 0;
BA_ "GenSigSendType" SG_ 819 ADS_4_Resd4 0;
BA_ "GenSigSendType" SG_ 819 ADS_4_SCFSwtSet 0;
BA_ "GenSigSendType" SG_ 819 ADS_4_AEBSettingSt 0;
BA_ "GenSigSendType" SG_ 819 ADS_4_FCWSettingSt 0;
BA_ "GenSigSendType" SG_ 819 ADS_4_DAISwtSet 0;
BA_ "GenSigSendType" SG_ 819 ADS_4_CruiseAccelerateSts 0;
BA_ "GenSigStartValue" SG_ 1172 ExternalTemperature_F 225;
BA_ "GenSigSendType" SG_ 1172 ExternalTemperature_F 0;
BA_ "GenSigStartValue" SG_ 1172 ExternalTemperature_C 254;
BA_ "GenSigInvalidValue" SG_ 1172 ExternalTemperature_C 254;
BA_ "GenSigSendType" SG_ 1172 ExternalTemperature_C 0;
BA_ "GenSigSendType" SG_ 1172 BlowSpeedLevelDisplaySts 0;
BA_ "GenSigStartValue" SG_ 1147 CCP_1_FLTempSwitchReq 31;
BA_ "GenSigInvalidValue" SG_ 1147 CCP_1_FLTempSwitchReq 31;
BA_ "GenSigSendType" SG_ 1147 CCP_1_FLTempSwitchReq 0;
BA_ "GenSigSendType" SG_ 1147 CCP_1_FrontAutoACSwitchReq 0;
BA_ "GenSigSendType" SG_ 1147 CCP_1_FrontOFFSwitchReq 0;
BA_ "GenSigSendType" SG_ 1147 CCP_1_FBlowSpdCtrlSwitchReq 0;
BA_ "GenSigSendType" SG_ 1147 FLCCP_MainSetHeatReq 0;
BA_ "GenSigSendType" SG_ 1147 FLCCP_MainSetVentilationReq 0;
BA_ "GenSigSendType" SG_ 1147 CCP_1_ACFastCool 0;
BA_ "GenSigSendType" SG_ 1107 TMS_PM25_Detect 0;
BA_ "GenSigStartValue" SG_ 1107 TMS_CCP_FLTempSts 31;
BA_ "GenSigInvalidValue" SG_ 1107 TMS_CCP_FLTempSts 31;
BA_ "GenSigSendType" SG_ 1107 TMS_CCP_FLTempSts 0;
BA_ "GenSigSendType" SG_ 1107 TMS_CCP_FrontAutoACSts 0;
BA_ "GenSigSendType" SG_ 1107 TMS_CCP_ACStatus 0;
BA_ "GenSigSendType" SG_ 1107 TMS_CCP_FrontOFFSts 0;
BA_ "GenSigSendType" SG_ 1107 TMS_CCP_FBlowSpdCtrlSts 0;
BA_ "GenSigStartValue" SG_ 1107 TMS_CCP_FRTempSts 31;
BA_ "GenSigInvalidValue" SG_ 1107 TMS_CCP_FRTempSts 31;
BA_ "GenSigSendType" SG_ 1107 TMS_CCP_FRTempSts 0;
BA_ "GenSigSendType" SG_ 1107 TMS_CCP_RecyMode 0;
BA_ "GenSigSendType" SG_ 1107 TMS_CCP_FrontDefrostSts 0;
BA_ "GenSigSendType" SG_ 1107 TMS_UVC_WorkingBfReq 0;
BA_ "GenSigSendType" SG_ 1107 TMS_UVC_LuminanceBfReq 0;
BA_ "GenSigSendType" SG_ 1107 TMS_CCP_ACFastCool 0;
BA_ "GenSigSendType" SG_ 1107 TMS_CCP_ACFastHeat 0;
BA_ "GenSigStartValue" SG_ 1175 CCP_2_FRTempSwitchReq 31;
BA_ "GenSigInvalidValue" SG_ 1175 CCP_2_FRTempSwitchReq 31;
BA_ "GenSigSendType" SG_ 1175 CCP_2_FRTempSwitchReq 0;
BA_ "GenSigSendType" SG_ 1175 CCP_2_RecyModeReq 0;
BA_ "GenSigSendType" SG_ 1175 CCP_2_DefrostModeSwitchReq 0;
BA_ "GenSigSendType" SG_ 1175 CCP_2_RearDefrostSwitchReq 0;
BA_ "GenSigSendType" SG_ 1175 CCP_2_ACFastHeat 0;
BA_ "GenSigSendType" SG_ 1175 CCP_2_FrontBlowSpdCtrlSwitchReq 0;
BA_ "GenSigSendType" SG_ 1175 FRCCP_DeputySetHeatReq 0;
BA_ "GenSigSendType" SG_ 1175 FRCCP_DeputySetVentilationReq 0;
BA_ "GenSigSendType" SG_ 1175 CCP_2_ACSwitchReq 0;
BA_ "GenSigSendType" SG_ 1175 FRCCP_ZoneSelectionKeyReq 0;
BA_ "GenSigSendType" SG_ 1292 CHB_App_Sts 0;
BA_ "GenSigSendType" SG_ 1292 CHB_AppMem_Sts 0;
BA_ "GenSigSendType" SG_ 1292 CHB_AppDelay_Sts 0;
BA_ "GenSigInvalidValue" SG_ 1292 CHB_AppTimeset_Sts 31;
BA_ "GenSigSendType" SG_ 1292 CHB_AppTimeset_Sts 0;
BA_ "GenSigSendType" SG_ 1292 CHB_AppCoolorheat_Sts 0;
BA_ "GenSigSendType" SG_ 1292 CHB_AppCoolset_Sts 0;
BA_ "GenSigSendType" SG_ 1292 CHB_AppHeatset_Sts 0;
BA_ "GenSigSendType" SG_ 1292 CHB_AppSterilization_Sts 0;
BA_ "GenSigSendType" SG_ 1292 CHB_AppItemsLeft_Sts 0;
BA_ "GenSigSendType" SG_ 1292 CHB_AppItemsLeftset_Sts 0;
BA_ "GenSigSendType" SG_ 1292 CHB_AppChbDoor_Sts 0;
BA_ "GenSigStartValue" SG_ 49 ACU_2_LateralAcceleration 2000;
BA_ "GenSigInvalidValue" SG_ 49 ACU_2_LateralAcceleration 65535;
BA_ "GenSigSendType" SG_ 49 ACU_2_LateralAcceleration 0;
BA_ "ASIL" SG_ 49 ACU_2_LateralAcceleration 3;
BA_ "GenSigStartValue" SG_ 49 ACU_2_YawRate 18000;
BA_ "GenSigInvalidValue" SG_ 49 ACU_2_YawRate 65535;
BA_ "GenSigSendType" SG_ 49 ACU_2_YawRate 0;
BA_ "ASIL" SG_ 49 ACU_2_YawRate 3;
BA_ "GenSigStartValue" SG_ 49 ACU_2_YawrateSigValidData 3;
BA_ "GenSigSendType" SG_ 49 ACU_2_YawrateSigValidData 0;
BA_ "ASIL" SG_ 49 ACU_2_YawrateSigValidData 3;
BA_ "GenSigStartValue" SG_ 49 ACU_2_LateralAccelerationSigVD 3;
BA_ "GenSigSendType" SG_ 49 ACU_2_LateralAccelerationSigVD 0;
BA_ "ASIL" SG_ 49 ACU_2_LateralAccelerationSigVD 3;
BA_ "GenSigSendType" SG_ 1024 CSunshadeSts 0;
BA_ "GenSigSendType" SG_ 1024 CSunshadePercentSts 0;
BA_ "GenSigSendType" SG_ 1024 FRZCU_SeatHeatLvlFR2 0;
BA_ "GenSigSendType" SG_ 1024 FRZCU_SeatVentLvlFR2 0;
BA_ "GenSigSendType" SG_ 1024 FRZCU_SeatVentLvlRR2 0;
BA_ "GenSigSendType" SG_ 1024 FRZCU_SeatHeatLvlRR2 0;
BA_ "GenSigSendType" SG_ 1024 FRZCU_ContainerlightSts 0;
BA_ "GenSigSendType" SG_ 1024 FRZCU_FRWinThermalSts 0;
BA_ "GenSigSendType" SG_ 1024 FRZCU_RRWinThermalSts 0;
BA_ "GenSigSendType" SG_ 1024 FRZCU_CSunshadeThermalSts 0;
BA_ "GenSigSendType" SG_ 1024 FRZCU_ADSLightSts 0;
BA_ "GenSigSendType" SG_ 1024 FRZCU_PasgerSeatMovFailCause 0;
BA_ "GenSigSendType" SG_ 1024 FRZCU_QueenSeatEnterSts 0;
BA_ "GenSigSendType" SG_ 1024 FRZCU_QueenSeatMovFailCause 0;
BA_ "GenSigSendType" SG_ 1024 FRZCU_QueenSeatSts 0;
BA_ "GenSigSendType" SG_ 1024 CSunshadeLearnedSts 0;
BA_ "GenSigStartValue" SG_ 1024 CSunshadePosn 127;
BA_ "GenSigInvalidValue" SG_ 1024 CSunshadePosn 127;
BA_ "GenSigSendType" SG_ 1024 CSunshadePosn 0;
BA_ "GenSigSendType" SG_ 1024 FRZCU_OnekeyHVoffSwtst 0;
BA_ "GenSigSendType" SG_ 290 EPS_1_CRC 0;
BA_ "GenSigSendType" SG_ 290 EPS_1_RollgCntr 0;
BA_ "GenSigSendType" SG_ 290 EPSFailSts 0;
BA_ "ASIL" SG_ 290 EPSFailSts 3;
BA_ "GenSigSendType" SG_ 290 EPSSteeringAngleCalibrationSts 0;
BA_ "GenSigSendType" SG_ 290 EPS_EOTLearning_Sts 0;
BA_ "GenSigSendType" SG_ 513 MFSL_UP_SW 0;
BA_ "GenSigSendType" SG_ 513 MFSL_DW_SW 0;
BA_ "GenSigSendType" SG_ 513 MFSL_Left_SW 0;
BA_ "GenSigSendType" SG_ 513 MFSL_Right_SW 0;
BA_ "GenSigSendType" SG_ 513 MFSL_OK_SW 0;
BA_ "GenSigSendType" SG_ 513 MFSL_AVM_SW 0;
BA_ "GenSigSendType" SG_ 513 MFSL_Customize 0;
BA_ "GenSigSendType" SG_ 513 MFSL_APA_SW 0;
BA_ "GenSigSendType" SG_ 513 MFSL_LCC_NCA_SW 0;
BA_ "GenSigStartValue" SG_ 1152 TBOX_PetmodeSetTemperature 31;
BA_ "GenSigInvalidValue" SG_ 1152 TBOX_PetmodeSetTemperature 31;
BA_ "GenSigSendType" SG_ 1152 TBOX_PetmodeSetTemperature 5;
BA_ "GenSigSendType" SG_ 1208 PPMID_1_PPMICounter 0;
BA_ "GenSigStartValue" SG_ 1208 PPMID_1_PPMISt 1;
BA_ "GenSigSendType" SG_ 1208 PPMID_1_PPMISt 0;
BA_ "GenSigStartValue" SG_ 1208 PPMID_1_HWSts 1;
BA_ "GenSigSendType" SG_ 1208 PPMID_1_HWSts 0;
BA_ "GenSigStartValue" SG_ 1208 PPMID_1_BSRBPASts 1;
BA_ "GenSigSendType" SG_ 1208 PPMID_1_BSRBPASts 0;
BA_ "GenSigSendType" SG_ 794 ADS_3_ICAStatus 0;
BA_ "GenSigSendType" SG_ 794 ADS_3_ICATextinfo 0;
BA_ "GenSigSendType" SG_ 794 ADS_3_ACCSts 0;
BA_ "GenSigSendType" SG_ 794 ADS_3_DriverHandsoffWarning 0;
BA_ "GenSigSendType" SG_ 794 ADS_3_LKSMod 0;
BA_ "GenSigSendType" SG_ 794 ADS_3_LKSSts 0;
BA_ "GenSigSendType" SG_ 794 ADS_3_ELKSts 0;
BA_ "GenSigSendType" SG_ 794 ADS_3_LKSLeftTrackingSt 0;
BA_ "GenSigSendType" SG_ 794 ADS_3_LKSRightTrackingSt 0;
BA_ "GenSigSendType" SG_ 794 ADS_3_ELKLeftActiveSt 0;
BA_ "GenSigSendType" SG_ 794 ADS_3_ELKRightActiveSt 0;
BA_ "GenSigSendType" SG_ 1155 ASU_3_horizontalSts 0;
BA_ "GenSigSendType" SG_ 1155 ASU_3_horizontalmodeFb 0;
BA_ "GenSigSendType" SG_ 789 ATCM_DriveModeSw 5;
BA_ "GenSigSendType" SG_ 789 ATCM_XModeSw 5;
BA_ "GenSigSendType" SG_ 789 ATCM_SwitchUTurnModeSet 5;
BA_ "GenSigSendType" SG_ 789 ATCM_ASU_LiftSet 5;
BA_ "GenSigSendType" SG_ 789 ATCM_ASU_LowerSet 5;
BA_ "GenSigSendType" SG_ 789 ATCM_ESP_OFF_SW 5;
BA_ "GenSigSendType" SG_ 789 ATCM_AVH_SW 5;
BA_ "GenSigSendType" SG_ 789 ATCM_AVM 5;
BA_ "GenSigSendType" SG_ 1214 BNCM_16_CRC1 1;
BA_ "GenSigSendType" SG_ 1214 BNCM_16_RollgCntr1 1;
BA_ "GenSigSendType" SG_ 1214 BNCM_16_Resd1 1;
BA_ "GenSigSendType" SG_ 1214 BNCM_16_CMD 1;
BA_ "GenSigSendType" SG_ 1214 BNCM_16_PDU1 1;
BA_ "GenSigSendType" SG_ 1214 BNCM_16_PDU2 1;
BA_ "GenSigSendType" SG_ 1214 BNCM_16_PDU3 1;
BA_ "GenSigSendType" SG_ 1214 BNCM_16_PDU4 1;
BA_ "GenSigSendType" SG_ 1095 RLCR_1_CRC1 0;
BA_ "GenSigSendType" SG_ 1095 RLCR_1_RollgCntr1 0;
BA_ "GenSigSendType" SG_ 1095 RLCR_1_Resd1 0;
BA_ "GenSigSendType" SG_ 1095 RLCR_1_SysSt 0;
BA_ "GenSigSendType" SG_ 1095 RLCR_1_BlkSts 0;
BA_ "GenSigSendType" SG_ 1095 RLCR_1_BSDWarn 0;
BA_ "GenSigSendType" SG_ 1095 RLCR_1_DOWWarn 0;
BA_ "GenSigSendType" SG_ 1095 RLCR_1_DowLock 0;
BA_ "GenSigSendType" SG_ 1095 RLCR_1_ELK_Collision_flag 0;
BA_ "GenSigSendType" SG_ 1095 RLCR_1_ELK_CollisionFlagValid 0;
BA_ "GenSigSendType" SG_ 1267 RRCR_1_CRC1 0;
BA_ "GenSigSendType" SG_ 1267 RRCR_1_RollgCntr1 0;
BA_ "GenSigSendType" SG_ 1267 RRCR_1_Resd1 0;
BA_ "GenSigSendType" SG_ 1267 RRCR_1_SysSt 0;
BA_ "GenSigSendType" SG_ 1267 RRCR_1_BlkSts 0;
BA_ "GenSigSendType" SG_ 1267 RRCR_1_BSDWarn 0;
BA_ "GenSigSendType" SG_ 1267 RRCR_1_DOWWarn 0;
BA_ "GenSigSendType" SG_ 1267 RRCR_1_DowLock 0;
BA_ "GenSigSendType" SG_ 1267 RRCR_1_ELK_Collision_flag 0;
BA_ "GenSigSendType" SG_ 1267 RRCR_1_ELK_CollisionFlagValid 0;
BA_ "GenSigSendType" SG_ 788 ADS_2_AEBStatus 0;
BA_ "GenSigSendType" SG_ 788 ADS_2_FCWStatus 0;
BA_ "GenSigSendType" SG_ 788 FCM_2_IHCfunctionSts 0;
BA_ "GenSigSendType" SG_ 571 LHTurnlightSts 0;
BA_ "ASIL" SG_ 571 LHTurnlightSts 3;
BA_ "GenSigSendType" SG_ 571 RHTurnlightSts 0;
BA_ "ASIL" SG_ 571 RHTurnlightSts 3;
BA_ "GenSigSendType" SG_ 571 LHFdoorSts 0;
BA_ "ASIL" SG_ 571 LHFdoorSts 2;
BA_ "GenSigStartValue" SG_ 571 LHFDoorLockSts 3;
BA_ "GenSigSendType" SG_ 571 LHFDoorLockSts 0;
BA_ "ASIL" SG_ 571 LHFDoorLockSts 2;
BA_ "GenSigSendType" SG_ 571 LHTurnSW 0;
BA_ "GenSigSendType" SG_ 571 RHTurnSW 0;
BA_ "GenSigSendType" SG_ 571 HazardLightSW 0;
BA_ "GenSigSendType" SG_ 571 LHFSeatBeltSW 0;
BA_ "ASIL" SG_ 571 LHFSeatBeltSW 2;
BA_ "GenSigSendType" SG_ 571 DirectionIndLeft 0;
BA_ "ASIL" SG_ 571 DirectionIndLeft 3;
BA_ "GenSigSendType" SG_ 571 DirectionIndRight 0;
BA_ "ASIL" SG_ 571 DirectionIndRight 3;
BA_ "GenSigSendType" SG_ 699 LHRdoorSts 0;
BA_ "ASIL" SG_ 699 LHRdoorSts 2;
BA_ "GenSigSendType" SG_ 787 ChrgHoodSts 0;
BA_ "GenSigSendType" SG_ 787 FRZCU_FRSitPosnSts 0;
BA_ "GenSigSendType" SG_ 524 ADS_6_Customize_buttonsFB 0;
BA_ "GenSigSendType" SG_ 572 ONEBOX_7_TAB_HighTemp 0;
BA_ "GenSigSendType" SG_ 572 ONEBOX_7_TAB_Active 0;
BA_ "GenSigSendType" SG_ 572 ONEBOX_7_BSW_Active 0;
BA_ "GenSigSendType" SG_ 572 ONEBOX_7_iCCO_TgtVel 0;
BA_ "GenSigSendType" SG_ 783 ADCC_SysReadySts 0;
BA_ "GenSigSendType" SG_ 1110 IMMO_Chall_ICC 2;
BA_ "GenSigSendType" SG_ 1149 IMMO_Teach_VCC 2;
BA_ "GenSigSendType" SG_ 1037 ADS_RCTAWarn_Left 0;
BA_ "GenSigSendType" SG_ 1037 ADS_RCTAWarn_Rigth 0;
BA_ "GenSigSendType" SG_ 1037 ADS_FCTAWarn_Left 0;
BA_ "GenSigSendType" SG_ 1037 ADS_FCTAWarn_Right 0;
BA_ "GenSigSendType" SG_ 943 CSA_3_CRC1 0;
BA_ "GenSigSendType" SG_ 943 CSA_3_RollgCntr1 0;
BA_ "GenSigSendType" SG_ 943 CSA_3_Resd1 0;
BA_ "GenSigInvalidValue" SG_ 943 FlwheelBearing 4095;
BA_ "GenSigSendType" SG_ 943 FlwheelBearing 0;
BA_ "GenSigInvalidValue" SG_ 943 FrwheelBearing 4095;
BA_ "GenSigSendType" SG_ 943 FrwheelBearing 0;
BA_ "GenSigInvalidValue" SG_ 943 BlwheelBearing 4095;
BA_ "GenSigSendType" SG_ 943 BlwheelBearing 0;
BA_ "GenSigInvalidValue" SG_ 943 BrwheelBearing 4095;
BA_ "GenSigSendType" SG_ 943 BrwheelBearing 0;
BA_ "GenSigSendType" SG_ 943 CSA_3_CRC2 0;
BA_ "GenSigSendType" SG_ 943 CSA_3_RollgCntr2 0;
BA_ "GenSigInvalidValue" SG_ 943 VehicleBearing_kg 4095;
BA_ "GenSigSendType" SG_ 943 VehicleBearing_kg 0;
BA_ "GenSigInvalidValue" SG_ 943 VehicleBearing_lb 4095;
BA_ "GenSigSendType" SG_ 943 VehicleBearing_lb 0;
BA_ "GenSigInvalidValue" SG_ 943 GoodsWeight_kg 4095;
BA_ "GenSigSendType" SG_ 943 GoodsWeight_kg 0;
BA_ "GenSigInvalidValue" SG_ 943 Goods_Weight_Ratio 1023;
BA_ "GenSigSendType" SG_ 943 Goods_Weight_Ratio 0;
BA_ "GenSigSendType" SG_ 943 CSA_3_CRC3 0;
BA_ "GenSigSendType" SG_ 943 CSA_3_RollgCntr3 0;
BA_ "GenSigSendType" SG_ 943 CSA_3_Resd3 0;
BA_ "GenSigInvalidValue" SG_ 943 GoodsWeight_lb 4095;
BA_ "GenSigSendType" SG_ 943 GoodsWeight_lb 0;
BA_ "GenSigInvalidValue" SG_ 943 OverWeightValue_kg 4095;
BA_ "GenSigSendType" SG_ 943 OverWeightValue_kg 0;
BA_ "GenSigInvalidValue" SG_ 943 OverWeightValue_lb 4095;
BA_ "GenSigSendType" SG_ 943 OverWeightValue_lb 0;
BA_ "GenSigSendType" SG_ 943 OverWeightRatio 0;
BA_ "GenSigSendType" SG_ 943 OverWeightWarning 0;
BA_ "GenSigSendType" SG_ 943 OverLoadWarnShieldSetFed 0;
BA_ "GenSigInvalidValue" SG_ 943 Fraxlebearingrate 255;
BA_ "GenSigSendType" SG_ 943 Fraxlebearingrate 0;
BA_ "GenSigInvalidValue" SG_ 1120 RLHS_2_AmbBrightness 4095;
BA_ "GenSigSendType" SG_ 1120 RLHS_2_AmbBrightness 0;
BA_ "GenSigSendType" SG_ 1120 RLHS_LiSwithReason 0;
BA_ "GenSigSendType" SG_ 850 ASU_6_HMIFailFb_JT 0;
BA_ "ASIL" SG_ 850 ASU_6_HMIFailFb_JT 3;
BA_ "GenSigSendType" SG_ 850 ASU_inflate_352h 0;
BA_ "GenSigSendType" SG_ 850 ASU_trekthrough_352h 0;
BA_ "GenSigSendType" SG_ 850 ASU_undergroundmode_352h 0;
BA_ "GenSigSendType" SG_ 1199 TCM_1_TrailerSts 0;
BA_ "ASIL" SG_ 1199 TCM_1_TrailerSts 3;
BA_ "GenSigSendType" SG_ 1131 ClutchTemperature_46Bh 0;
BA_ "GenSigSendType" SG_ 1131 GBFaultstatus_46Bh 0;
BA_ "GenSigInvalidValue" SG_ 1131 GBPositoionDisplay_46Bh 31;
BA_ "GenSigSendType" SG_ 1131 GBPositoionDisplay_46Bh 0;
BA_ "GenSigSendType" SG_ 1060 InforDisplay_424h 0;
BA_ "GenSigStartValue" SG_ 1129 EngineCoolantTemp_469h 91;
BA_ "GenSigInvalidValue" SG_ 1129 EngineCoolantTemp_469h 255;
BA_ "GenSigSendType" SG_ 1129 EngineCoolantTemp_469h 0;
BA_ "GenSigInvalidValue" SG_ 1129 EngineSpeed_469h 2047;
BA_ "GenSigSendType" SG_ 1129 EngineSpeed_469h 0;
BA_ "GenSigSendType" SG_ 1129 EngineSpeedValidData_469h 0;
BA_ "GenSigSendType" SG_ 1128 PromptMesg_468h 0;
BA_ "GenSigSendType" SG_ 1018 FLZCU_KeyDriveModememory_3FAh 0;
BA_ "GenSigSendType" SG_ 1018 FLZCU_DriveModeChangeFail_3FAh 0;
BA_ "GenSigSendType" SG_ 1018 FLZCU_DraggingModeRemind_3FAh 0;
BA_ "GenSigSendType" SG_ 1018 FLZCU_CCOSwtFed_3FAh 0;
BA_ "GenSigSendType" SG_ 1018 FLZCU_CCO_TextDisp_3FAh 0;
BA_ "GenSigSendType" SG_ 1018 FLZCU_DriveMode_3FAh 0;
BA_ "GenSigSendType" SG_ 1123 ISS_Switch_Sts_463h 0;
BA_ "GenSigSendType" SG_ 1972 Diag_FLZCU_RES 2;
BA_ "GenSigSendType" SG_ 1844 Diag_FLZCU_REQ 2;
VAL_ 819 ADS_4_AEBStatus 0 "OFF" 1 "ON" 2 "Failure" 3 "available" 4 "active" 5 "pre-fill" 6 "blindness" 7 "Reserved" ;
VAL_ 819 ADS_4_ACCSts 0 "Off" 1 "Passive" 2 "Standby" 3 "Active_Control" 4 "BrakeOnly" 5 "Override" 6 "StandWait" 7 "failure" 8 "StandActive" 9 "reserved" 10 "reserved" 11 "reserved" 12 "reserved" 13 "reserved" 14 "reserved" 15 "reserved" ;
VAL_ 819 ADS_4_TimeGapSet 0 "None" 1 "Time Gap1" 2 "Time Gap2" 3 "Time Gap3" 4 "Time Gap4" 5 "Time Gap5" 6 "Reserved" 7 "Reserved" ;
VAL_ 819 ADS_4_FcwMode 0 "OFF" 1 "ON" 2 "Failure" 3 "Active" 4 "blindness" 5 "Reserved" 6 "Reserved" 7 "Reserved" ;
VAL_ 819 ADS_4_AEBReqType 0 "NoReq" 1 "AEBm" 2 "AEBp" 3 "AEBVru" 4 "EBA" 5 "LTA" 6 "CPTA" 7 "Reserved" ;
VAL_ 819 ADS_4_SetSpd 255 "Invalid" ;
VAL_ 819 ADS_4_DAIStatus 0 "On" 1 "Off" 2 "Failure" 3 "None" ;
VAL_ 819 ADS_4_ACCTextMessage 0 "No Display" 1 "ACC Activated" 2 "ACC Cannot Be Activated" 3 "ACC Cancelled" 4 "ACC failure" 5 "Weather abnormal" 6 "Driver Override" 7 "Active Decelerate" 8 "Cruise speed can not be added" 9 "ACC abort and take over request" 10 "Maximum decelerate to ahead speed sign" 11 "System add timegap to front big vehicle" 12 "Cut in reminder" 13 "Large curve remider" 14 "Auto drive off reminder" 15 "takeover timeout" ;
VAL_ 819 ADS_4_LongiTakeOverReq 0 "No Request" 1 "Request" ;
VAL_ 819 ADS_4_SetSpdUnit 0 "Km/h" 1 "Mile/h" ;
VAL_ 819 ADS_4_GoNotifier 0 "None" 1 "Go Notifier" 2 "Go Visual Notifier" 3 "Handson visual warning" 4 "Handson and DMS warning" 5 "Press gas reminder" 6 "Reserved" 7 "Reserved" ;
VAL_ 819 ADS_4_DAISts 0 "None" 1 "active Drive Off" 2 "Reserved" 3 "Reserved" ;
VAL_ 819 ADS_4_Radar_textinfo 0 "Radar normal" 1 "Radar failure" 2 "Radar blocked" 3 "Reserved" 4 "Reserved" 5 "Reserved" 6 "Reserved" 7 "Reserved" ;
VAL_ 819 ADS_4_SCF_PopoverReq 0 "No Request" 1 "Driver confirm Request" ;
VAL_ 819 ADS_4_DrvrCfmSCFDispFb 0 "not confirmed" 1 "confirme" ;
VAL_ 819 ADS_4_SCF_SpdLimUnit 0 "Unknown" 1 "km/h" 2 "Miles/h" 3 "Reserved" ;
VAL_ 819 ADS_4_SCF_SpdLimSts 0 "OFF" 1 "STANDBY" 2 "ACTIVE" 3 "REVERSIBLE_FAILURE" 4 "IREVERSIBLE FAILURE" 5 "Reserved" 6 "Reserved" 7 "Reserved" ;
VAL_ 819 ADS_4_ACCObjTyp 0 "No type" 1 "Car" 2 "Truck" 3 "Motorcycle" 4 "Pedestrian" 5 "Cyclist" 6 "Bus" 7 "Reserved" 8 "Reserved" 9 "Reserved" 10 "Reserved" 11 "Reserved" 12 "Reserved" 13 "Reserved" 14 "Reserved" 15 "Reserved" ;
VAL_ 819 ADS_4_FrntFarObjTyp 0 "No type" 1 "Car" 2 "Truck" 3 "Motorcycle" 4 "Pedestrian" 5 "Cyclist" 6 "Bus" 7 "Reserved" 8 "Reserved" 9 "Reserved" 10 "Reserved" 11 "Reserved" 12 "Reserved" 13 "Reserved" 14 "Reserved" 15 "Reserved" ;
VAL_ 819 ADS_4_FrntFarObjID 0 "Invalid" 1 "Valid" ;
VAL_ 819 ADS_4_ACCObjID 0 "Invalid" 1 "Valid" ;
VAL_ 819 ADS_4_LeObjID 0 "Invalid" 1 "Valid" ;
VAL_ 819 ADS_4_LeObjTyp 0 "No type" 1 "Car" 2 "Truck" 3 "Motorcycle" 4 "Pedestrian" 5 "Cyclist" 6 "Bus" 7 "Reserved" 8 "Reserved" 9 "Reserved" 10 "Reserved" 11 "Reserved" 12 "Reserved" 13 "Reserved" 14 "Reserved" 15 "Reserved" ;
VAL_ 819 ADS_4_RiObjID 0 "Invalid" 1 "Valid" ;
VAL_ 819 ADS_4_RiObjTyp 0 "No type" 1 "Car" 2 "Truck" 3 "Motorcycle" 4 "Pedestrian" 5 "Cyclist" 6 "Bus" 7 "Reserved" 8 "Reserved" 9 "Reserved" 10 "Reserved" 11 "Reserved" 12 "Reserved" 13 "Reserved" 14 "Reserved" 15 "Reserved" ;
VAL_ 819 ADS_4_SCFSwtSet 0 "None" 1 "ON" 2 "Off" 3 "reserved" ;
VAL_ 819 ADS_4_AEBSettingSt 0 "None" 1 "ON" 2 "Off" 3 "reserved" ;
VAL_ 819 ADS_4_FCWSettingSt 0 "None" 1 "Off" 2 "high" 3 "middle" 4 "low" 5 "reserved" 6 "reserved" 7 "reserved" ;
VAL_ 819 ADS_4_DAISwtSet 0 "None" 1 "ON" 2 "Off" 3 "reserved" ;
VAL_ 819 ADS_4_CruiseAccelerateSts 0 "None" 1 "Accelerating" 2 "Decelerating" 3 "Reserved" ;
VAL_ 1172 ExternalTemperature_C 254 "invalid" ;
VAL_ 1172 BlowSpeedLevelDisplaySts 0 "Not_Active" 1 "Level_1" 2 "Level_2" 3 "Level_3" 4 "Level_4" 5 "Level_5" 6 "Level_6" 7 "Level_7" 8 "Level_8" 9 "Level_9" 10 "Level_10" 11 "Reserved" 12 "Level_0" 13 "Reserved" 14 "Reserved" 15 "Reserved" ;
VAL_ 1147 CCP_1_FrontAutoACSwitchReq 0 "No_Pressed" 1 "Pressed" ;
VAL_ 1147 CCP_1_FrontOFFSwitchReq 0 "No_Pressed" 1 "Pressed" ;
VAL_ 1147 CCP_1_FBlowSpdCtrlSwitchReq 0 "No_Request" 1 "Speed_1_Request" 2 "Speed_2_Request" 3 "Speed_3_Request" 4 "Speed_4_Request" 5 "Speed_5_Request" 6 "Speed_6_Request" 7 "Speed_7_Request" 8 "Speed_8_Request" 9 "Speed_9_Request" 10 "Speed_10_Request" 12 "Speed_0_Request" 15 "Invalid" ;
VAL_ 1147 FLCCP_MainSetHeatReq 0 "Not_Active" 1 "OFF" 2 "Seat_heating_Level1" 3 "Seat_heating_Level2" 4 "Seat_heating_Level3" ;
VAL_ 1147 FLCCP_MainSetVentilationReq 0 "Not_Active" 1 "OFF" 2 "Seat_Ventilation_Level1" 3 "Seat_Ventilation_Level2" 4 "Seat_Ventilation_Level3" ;
VAL_ 1147 CCP_1_ACFastCool 0 "Not_Active" 1 "On" 2 "Off" 3 "Not_Used" ;
VAL_ 1107 TMS_PM25_Detect 0 "NotActive" 1 "Active" ;
VAL_ 1107 TMS_CCP_FrontAutoACSts 0 "NotActive" 1 "Active" ;
VAL_ 1107 TMS_CCP_ACStatus 0 "NotActive" 1 "Active" ;
VAL_ 1107 TMS_CCP_FrontOFFSts 0 "NotActive" 1 "Active" ;
VAL_ 1107 TMS_CCP_FBlowSpdCtrlSts 0 "No_Request" 1 "Speed_1_Request" 2 "Speed_2_Request" 3 "Speed_3_Request" 4 "Speed_4_Request" 5 "Speed_5_Request" 6 "Speed_6_Request" 7 "Speed_7_Request" 8 "Speed_8_Request" 9 "Speed_9_Request" 10 "Speed_10_Request" 12 "Speed_0_Request" 15 "Invalid" ;
VAL_ 1107 TMS_CCP_RecyMode 0 "no_Request" 1 "internal_Recycle_Request" 2 "external_Recycle_Request" 3 "auto_Recycle_Request" ;
VAL_ 1107 TMS_CCP_FrontDefrostSts 0 "NotActive" 1 "Active" ;
VAL_ 1107 TMS_UVC_WorkingBfReq 0 "No_Request" 1 "Open_Request" 2 "Close_Request" 3 "AUTO" ;
VAL_ 1107 TMS_UVC_LuminanceBfReq 0 "No_Request" 1 "Higher" 2 "Lower" 3 "Reserved" ;
VAL_ 1107 TMS_CCP_ACFastCool 0 "Not_Active" 1 "ON" 2 "OFF" 3 "Not_Used" ;
VAL_ 1107 TMS_CCP_ACFastHeat 0 "Not_Active" 1 "ON" 2 "OFF" 3 "Not_Used" ;
VAL_ 1175 CCP_2_RecyModeReq 0 "no_Request" 1 "internal_Recycle_Request" 2 "external_Recycle_Request" ;
VAL_ 1175 CCP_2_DefrostModeSwitchReq 0 "No_Pressed" 1 "Pressed" ;
VAL_ 1175 CCP_2_RearDefrostSwitchReq 0 "No_Pressed" 1 "Pressed" ;
VAL_ 1175 CCP_2_ACFastHeat 0 "Not_Active" 1 "ON" 2 "OFF" 3 "Not_Used" ;
VAL_ 1175 CCP_2_FrontBlowSpdCtrlSwitchReq 0 "No_Request" 1 "Speed_1_Request" 2 "Speed_2_Request" 3 "Speed_3_Request" 4 "Speed_4_Request" 5 "Speed_5_Request" 6 "Speed_6_Request" 7 "Speed_7_Request" 8 "Speed_8_Request" 9 "Speed_9_Request" 10 "Speed_10_Request" 12 "Speed_0_Request" 15 "Invalid" ;
VAL_ 1175 FRCCP_DeputySetHeatReq 0 "Not_Active" 1 "OFF" 2 "Seat_heating_Level1" 3 "Seat_heating_Level2" 4 "Seat_heating_Level3" ;
VAL_ 1175 FRCCP_DeputySetVentilationReq 0 "Not_Active" 1 "OFF" 2 "Seat_Ventilation_Level1" 3 "Seat_Ventilation_Level2" 4 "Seat_Ventilation_Level3" ;
VAL_ 1175 CCP_2_ACSwitchReq 0 "No_Pressed" 1 "Pressed" ;
VAL_ 1175 FRCCP_ZoneSelectionKeyReq 0 "No_Pressed" 1 "Pressed" ;
VAL_ 1292 CHB_App_Sts 0 "NotActive" 1 "Chb_ON" 2 "Chb_OFF" 3 "reserved" ;
VAL_ 1292 CHB_AppMem_Sts 0 "NotActive" 1 "ChbMem_ON" 2 "ChbMem_OFF" 3 "reserved" ;
VAL_ 1292 CHB_AppDelay_Sts 0 "NotActive" 1 "ChbDelay_ON" 2 "ChbDelay_OFF" 3 "reserved" ;
VAL_ 1292 CHB_AppCoolorheat_Sts 0 "NotActive" 1 "ChbCool_on" 2 "ChbHeat_on" 3 "Close" 4 "ColdDrinkMode" 5 "IceCreamMode" 6 "WarmMilkMode" 7 "WarmDrinkMode" ;
VAL_ 1292 CHB_AppCoolset_Sts 0 "Not_Active" 1 "ChbCoolset_-6" 2 "ChbCoolset_-5" 3 "ChbCoolset_-4" 4 "ChbCoolset_-3" 5 "ChbCoolset_-2" 6 "ChbCoolset_-1" 7 "ChbCoolset_0" 8 "ChbCoolset_1" 9 "ChbCoolset_2" 10 "ChbCoolset_3" 11 "ChbCoolset_4" 12 "ChbCoolset_5" 13 "ChbCoolset_6" 14 "ChbCoolset_-18" 15 "ChbCoolset_-17" 16 "ChbCoolset_-16" 17 "ChbCoolset_-15" 18 "ChbCoolset_-14" 19 "ChbCoolset_-13" 20 "ChbCoolset_-12" 21 "ChbCoolset_-11" 22 "ChbCoolset_-10" 23 "ChbCoolset_-9" 24 "ChbCoolset_-8" 25 "ChbCoolset_-7" 26 "Reserved" 27 "Reserved" 28 "Reserved" 29 "Reserved" 30 "Reserved" 31 "Reserved" ;
VAL_ 1292 CHB_AppHeatset_Sts 0 "Not_Active" 1 "ChbHeatset_35" 2 "ChbHeatset_36" 3 "ChbHeatset_37" 4 "ChbHeatset_38" 5 "ChbHeatset_39" 6 "ChbHeatset_40" 7 "ChbHeatset_41" 8 "ChbHeatset_42" 9 "ChbHeatset_43" 10 "ChbHeatset_44" 11 "ChbHeatset_45" 12 "ChbHeatset_46" 13 "ChbHeatset_47" 14 "ChbHeatset_48" 15 "ChbHeatset_49" 16 "ChbHeatset_50" ;
VAL_ 1292 CHB_AppSterilization_Sts 0 "NotActive" 1 "Chbsterilize_ON" 2 "Chbsterilize_OFF" 3 "Chbsterilize_Stop" ;
VAL_ 1292 CHB_AppItemsLeft_Sts 0 "NotActive" 1 "ChbItemsLeft_ON" 2 "ChbItemsLeft_OFF" 3 "reserved" ;
VAL_ 1292 CHB_AppItemsLeftset_Sts 0 "NotActive" 1 "CHB_ItemsLeftset_ON" 2 "CHB_ItemsLeftset_OFF" 3 "Reserved" ;
VAL_ 1292 CHB_AppChbDoor_Sts 0 "NotActive" 1 "ChbDoor_ON" 2 "ChbDoor_OFF" 3 "reserved" ;
VAL_ 49 ACU_2_LateralAcceleration 65535 "Invalid" ;
VAL_ 49 ACU_2_YawRate 65535 "Invalid" ;
VAL_ 49 ACU_2_YawrateSigValidData 0 "Valid" 1 "Reserved" 2 "Invalid" 3 "Initialize" ;
VAL_ 49 ACU_2_LateralAccelerationSigVD 0 "Valid" 1 "Reserved" 2 "Invalid" 3 "Initialize" ;
VAL_ 1024 CSunshadeSts 0 "Not Active" 1 "Open" 2 "Close" 3 "Half_Open" 4 "Opening" 5 "Closing" 6 "Stop" 7 "Error" ;
VAL_ 1024 CSunshadePercentSts 0 "Not Active" 1 "0%" 2 "10%" 3 "20%" 4 "30%" 5 "40%" 6 "50%" 7 "60%" 8 "70%" 9 "80%" 10 "90%" 11 "100%" 12 "reserved" 13 "reserved" 14 "reserved" 15 "reserved" ;
VAL_ 1024 FRZCU_SeatHeatLvlFR2 0 "Not Active" 1 "OFF" 2 "Level1" 3 "Level2" 4 "Level3" 5 "Level4" 6 "Level5" 7 "Level6" 8 "Level7" 9 "Level8" 10 "Level9" ;
VAL_ 1024 FRZCU_SeatVentLvlFR2 0 "Not Active" 1 "OFF" 2 "Level1" 3 "Level2" 4 "Level3" 5 "Level4" 6 "Level5" 7 "Level6" 8 "Level7" 9 "Level8" 10 "Level9" ;
VAL_ 1024 FRZCU_SeatVentLvlRR2 0 "Not Active" 1 "OFF" 2 "Level1" 3 "Level2" 4 "Level3" 5 "Level4" 6 "Level5" 7 "Level6" 8 "Level7" 9 "Level8" 10 "Level9" ;
VAL_ 1024 FRZCU_SeatHeatLvlRR2 0 "Not Active" 1 "OFF" 2 "Level1" 3 "Level2" 4 "Level3" 5 "Level4" 6 "Level5" 7 "Level6" 8 "Level7" 9 "Level8" 10 "Level9" ;
VAL_ 1024 FRZCU_ContainerlightSts 0 "Not Active" 1 "ON" 2 "OFF" 3 "reserved" ;
VAL_ 1024 FRZCU_FRWinThermalSts 0 "Normal" 1 "Thermal protection" ;
VAL_ 1024 FRZCU_RRWinThermalSts 0 "Normal" 1 "Thermal protection" ;
VAL_ 1024 FRZCU_CSunshadeThermalSts 0 "Normal" 1 "Thermal protection" ;
VAL_ 1024 FRZCU_ADSLightSts 0 "OFF" 1 "ON" 2 "Reserved" 3 "Reserved" ;
VAL_ 1024 FRZCU_PasgerSeatMovFailCause 0 "Not active" 1 "Not Learned" 2 "Antipinch event" 3 "Hard Switch Not Released" 4 "Fold_Sts" 5 "Motor Circuit Failure" 6 "Low Priority" ;
VAL_ 1024 FRZCU_QueenSeatEnterSts 0 "Not Active" 1 "Running" 2 "Running Success" 3 "Running Fail" ;
VAL_ 1024 FRZCU_QueenSeatMovFailCause 0 "Not active" 1 "Not Learned" 2 "Antipinch event" 3 "Hard Switch Not Released" 4 "Fold_Sts" 5 "Motor Circuit Failure" 6 "Low Priority" 7 "RRSeatExpSts" 8 "RRSeat Occupied" 9 "RRSeatStop" ;
VAL_ 1024 FRZCU_QueenSeatSts 0 "Not Active" 1 "Exited" 2 "Entered" ;
VAL_ 1024 CSunshadeLearnedSts 0 "Not Active" 1 "Learned" 2 "Not Learned" 3 "Learning" ;
VAL_ 1024 FRZCU_OnekeyHVoffSwtst 0 "Not Pressed" 1 "Pressed" 2 "Stuck" 3 "Not Used" ;
VAL_ 290 EPSFailSts 0 "Not present" 1 "Fail present" 2 "Reserved" 3 "Reserved" ;
VAL_ 290 EPSSteeringAngleCalibrationSts 0 "Calibration is fine" 1 "No calibration or no initialization" ;
VAL_ 290 EPS_EOTLearning_Sts 0 "Learnt" 1 "Not Learnt" ;
VAL_ 513 MFSL_UP_SW 0 "Not_action" 1 "Pressed" 2 "Stuck" 3 "invalid" ;
VAL_ 513 MFSL_DW_SW 0 "Not_action" 1 "Pressed" 2 "Stuck" 3 "invalid" ;
VAL_ 513 MFSL_Left_SW 0 "Not_action" 1 "Pressed" 2 "Stuck" 3 "invalid" ;
VAL_ 513 MFSL_Right_SW 0 "Not_action" 1 "Pressed" 2 "Stuck" 3 "invalid" ;
VAL_ 513 MFSL_OK_SW 0 "Not_action" 1 "Pressed" 2 "Stuck" 3 "invalid" ;
VAL_ 513 MFSL_AVM_SW 0 "Not_action" 1 "Pressed" 2 "Stuck" 3 "invalid" ;
VAL_ 513 MFSL_Customize 0 "Not_action" 1 "Pressed" 2 "Stuck" 3 "invalid" ;
VAL_ 513 MFSL_APA_SW 0 "Not_action" 1 "Pressed" 2 "Stuck" 3 "invalid" ;
VAL_ 513 MFSL_LCC_NCA_SW 0 "Not_action" 1 "Pressed" 2 "Stuck" 3 "invalid" ;
VAL_ 1208 PPMID_1_PPMICounter 0 "Count not full" 1 "Count is full" ;
VAL_ 1208 PPMID_1_PPMISt 0 "PPMI no error" 1 "PPMI initialization" 2 "PPMI internal error" 3 "External error" 4 "Reserved" 5 "Reserved" 6 "Reserved" 7 "Reserved" ;
VAL_ 1208 PPMID_1_HWSts 0 "Not active" 1 "ON" 2 "OFF" 3 "Reserved" ;
VAL_ 1208 PPMID_1_BSRBPASts 0 "Not active" 1 "ON" 2 "OFF" 3 "Reserved" ;
VAL_ 794 ADS_3_ICAStatus 0 "Off" 1 "Passive" 2 "Standby" 3 "Active" 4 "Failure" 5 "Suspend" 6 "reserved" 7 "reserved" ;
VAL_ 794 ADS_3_ICATextinfo 0 "No dispaly" 1 "TJAICA Activated" 2 "TJAICA Cannot Be Activated" 3 "TJAICA Cancelled" 4 "TJAICA failure" 5 "TJAICA Suspend" 6 "TJAICA resumed" 7 "TJAICA degrade to ACC" 8 "Urgent TOR request" 9 "uncentered" 10 "Too Large curve" 11 "Abnormal tire pressure" 12 "Camera block" 13 "Master switch is off" 14 "reserved" 15 "reserved" ;
VAL_ 794 ADS_3_ACCSts 0 "Off" 1 "Passive" 2 "Standby" 3 "Active_Control" 4 "Brake Only" 5 "Override" 6 "Stand Wait" 7 "failure" 8 "Stand Active" 9 "reserved" 10 "reserved" 11 "reserved" 12 "reserved" 13 "reserved" 14 "reserved" 15 "reserved" ;
VAL_ 794 ADS_3_DriverHandsoffWarning 0 "None" 1 "Warning 1 for stage1" 2 "Warning 2  for stage2" 3 "Warning 3 for stage3(TOR)" 4 "Warning 4 for stage4(Punishment)" 5 "reserved" 6 "reserved" 7 "reserved" ;
VAL_ 794 ADS_3_LKSMod 0 "Off" 1 "Warning" 2 "Warning+intervention" 3 "reserved" ;
VAL_ 794 ADS_3_LKSSts 0 "OFF" 1 "Standby" 2 "Active" 3 "Failure" 4 "Passive" 5 "Reserved" 6 "Blindness(捷途使用)" 7 "Reserved" ;
VAL_ 794 ADS_3_ELKSts 0 "OFF" 1 "Standby" 2 "Active" 3 "Failure" 4 "Passive" 5 "Reserved" 6 "Blindness(捷途使用)" 7 "Reserved" ;
VAL_ 794 ADS_3_LKSLeftTrackingSt 0 "Inactive" 1 "Lane Tracking" 2 "Intervention" 3 "warning" ;
VAL_ 794 ADS_3_LKSRightTrackingSt 0 "Inactive" 1 "Lane Tracking" 2 "Intervention" 3 "warning" ;
VAL_ 794 ADS_3_ELKLeftActiveSt 0 "no warning" 1 "tracking" 2 "intervention" ;
VAL_ 794 ADS_3_ELKRightActiveSt 0 "no warning" 1 "tracking" 2 "intervention" ;
VAL_ 1155 ASU_3_horizontalSts 0 "Not Active" 1 "ON" 2 "OFF" 3 "Not use" ;
VAL_ 1155 ASU_3_horizontalmodeFb 0 "Not Active" 1 "Working" 2 "Complete" 3 "Abort" 4 "Failure" 5 "Reserved" 6 "Reserved" 7 "Reserved" ;
VAL_ 789 ATCM_DriveModeSw 0 "Not Active" 1 "Plus" 2 "Minus" 3 "Reserved" ;
VAL_ 789 ATCM_XModeSw 0 "Not_Active" 1 "ON" 2 "OFF" 3 "Reserved" ;
VAL_ 789 ATCM_SwitchUTurnModeSet 0 "Release" 1 "Press" ;
VAL_ 789 ATCM_ASU_LiftSet 0 "Release" 1 "Plus" ;
VAL_ 789 ATCM_ASU_LowerSet 0 "Not Active" 1 "Minus" ;
VAL_ 789 ATCM_ESP_OFF_SW 0 "Release" 1 "Press" ;
VAL_ 789 ATCM_AVH_SW 0 "Release" 1 "Press" ;
VAL_ 789 ATCM_AVM 0 "Release" 1 "Press" ;
VAL_ 1095 RLCR_1_SysSt 0 "Off" 1 "On" 2 "Temporary Error" 3 "System Error" ;
VAL_ 1095 RLCR_1_BlkSts 0 "Not Blockage" 1 "Blockage" ;
VAL_ 1095 RLCR_1_BSDWarn 0 "No Warning" 1 "Standard Warning" 2 "Critical Warning" 3 "Not Used" ;
VAL_ 1095 RLCR_1_DOWWarn 0 "No Warning" 1 "Level1 Warning" 2 "Level2 Warning" 3 "Not Used" ;
VAL_ 1095 RLCR_1_DowLock 0 "No Warning" 1 "Dow lock" 2 "Dow unlock" 3 "Not Used" ;
VAL_ 1095 RLCR_1_ELK_Collision_flag 0 "No critical situation of collision" 1 "Critical situation of collision" ;
VAL_ 1095 RLCR_1_ELK_CollisionFlagValid 0 "Not valid" 1 "Valid" ;
VAL_ 1267 RRCR_1_SysSt 0 "Off" 1 "On" 2 "Temporary Error" 3 "System Error" ;
VAL_ 1267 RRCR_1_BlkSts 0 "Not Blockage" 1 "Blockage" ;
VAL_ 1267 RRCR_1_BSDWarn 0 "No Warning" 1 "Standard Warning" 2 "Critical Warning" 3 "Not Used" ;
VAL_ 1267 RRCR_1_DOWWarn 0 "No Warning" 1 "Level1 Warning" 2 "Level2 Warning" 3 "Not Used" ;
VAL_ 1267 RRCR_1_DowLock 0 "No Warning" 1 "Dow lock" 2 "Dow unlock" 3 "Not Used" ;
VAL_ 1267 RRCR_1_ELK_Collision_flag 0 "No critical situation of collision" 1 "Critical situation of collision" ;
VAL_ 1267 RRCR_1_ELK_CollisionFlagValid 0 "Not valid" 1 "Valid" ;
VAL_ 788 ADS_2_AEBStatus 0 "OFF" 1 "ON" 2 "Failure" 3 "available" 4 "active" 5 "pre-fill" 6 "blindness" ;
VAL_ 788 ADS_2_FCWStatus 0 "no request" 1 "level 1(low)" 2 "level 2(middle)" 3 "level 3(high)" 4 "reserved" 5 "reserved" 6 "reserved" 7 "reserved" ;
VAL_ 788 FCM_2_IHCfunctionSts 0 "Off" 1 "Standby" 2 "Active" 3 "Fault" 4 "Reserved" 5 "Reserved" 6 "Reserved" 7 "Reserved" ;
VAL_ 571 LHTurnlightSts 0 "Not Active" 1 "Active" ;
VAL_ 571 RHTurnlightSts 0 "Not Active" 1 "Active" ;
VAL_ 571 LHFdoorSts 0 "Close" 1 "Ajar" 2 "full_open" 3 "Reserved" ;
VAL_ 571 LHFDoorLockSts 0 "Locked" 1 "Unlocked" 2 "Superlocked" 3 "Unknown" ;
VAL_ 571 LHTurnSW 0 "Off" 1 "Active" ;
VAL_ 571 RHTurnSW 0 "Off" 1 "Active" ;
VAL_ 571 HazardLightSW 0 "Close" 1 "Open" ;
VAL_ 571 LHFSeatBeltSW 0 "Not Active" 1 "Active" ;
VAL_ 571 DirectionIndLeft 0 "Close" 1 "Open" ;
VAL_ 571 DirectionIndRight 0 "Close" 1 "Open" ;
VAL_ 699 LHRdoorSts 0 "Close" 1 "Ajar" 2 "full_open" 3 "Reserved" ;
VAL_ 787 ChrgHoodSts 0 "Close" 1 "Open" ;
VAL_ 787 FRZCU_FRSitPosnSts 0 "Not Active" 1 "Location1" 2 "Location2" 3 "Location3" ;
VAL_ 524 ADS_6_Customize_buttonsFB 0 "Not Active" 1 "APA" 2 "TJA/ICA/ACC/NOA" 3 "Offroad AutoPilot" 4 "HPA" 5 "Not used" 6 "Not used" 7 "Not used" ;
VAL_ 572 ONEBOX_7_TAB_HighTemp 0 "No Active" 1 "Active" ;
VAL_ 572 ONEBOX_7_TAB_Active 0 "Not Active" 1 "Active" 2 "Stand by" 3 "Failed" ;
VAL_ 572 ONEBOX_7_BSW_Active 0 "Not Active" 1 "Active" 2 "Filed" 3 "initialize" ;
VAL_ 783 ADCC_SysReadySts 0 "Ready" 1 "not Ready" ;
VAL_ 1037 ADS_RCTAWarn_Left 0 "No Warning" 1 "Warning" ;
VAL_ 1037 ADS_RCTAWarn_Rigth 0 "No Warning" 1 "Warning" ;
VAL_ 1037 ADS_FCTAWarn_Left 0 "No Warning" 1 "Warning" ;
VAL_ 1037 ADS_FCTAWarn_Right 0 "No Warning" 1 "Warning" ;
VAL_ 943 OverWeightRatio 0 "未超载" 1 "超载0-10%" 2 "超载10%~20%" 3 "超载20%~30%" 4 "超载30%`40%" 5 "严重超载" 6 "Reserved" 7 "Reserved" ;
VAL_ 943 OverWeightWarning 0 "No warning" 1 "Warning" ;
VAL_ 943 OverLoadWarnShieldSetFed 0 "Not Active" 1 "ON" 2 "OFF" 3 "Fault" ;
VAL_ 1120 RLHS_2_AmbBrightness 4095 "Invalid" ;
VAL_ 1120 RLHS_LiSwithReason 0 "Darkstart" 1 "Day" 2 "Night" 3 "Tunnul" ;
VAL_ 850 ASU_6_HMIFailFb_JT 0 "Not_Active" 1 "SUSP_IS_lock" 2 "PLG_is_open" 3 "suspension_height_disable" 4 "suspension_damping_disable" 5 "Altitude_too_high" 6 "Pump_worked_out" 7 "The_pump_is_working_abnormally" 8 "Off-road_trekking_not_active" 9 "Off-road_trekking_out" 10 "Inflate_not_active" 11 "Undergroundmode_not_active" 12 "Undergroundmode_out" 13 "reserved" 14 "reserved" 15 "reserved" ;
VAL_ 850 ASU_inflate_352h 0 "No_Active" 1 "ON" 2 "OFF" 3 "not_used" ;
VAL_ 850 ASU_trekthrough_352h 0 "No_Active" 1 "ON" 2 "OFF" 3 "not_used" ;
VAL_ 850 ASU_undergroundmode_352h 0 "No_Active" 1 "ON" 2 "OFF" 3 "not_used" ;
VAL_ 1199 TCM_1_TrailerSts 0 "Disconnect" 1 "Connect" ;
VAL_ 1131 ClutchTemperature_46Bh 0 "Normal" 1 "Over" 2 "Super over" 3 "Not used" ;
VAL_ 1131 GBFaultstatus_46Bh 0 "No failure" 1 "GB failure" 2 "High oil over temperature" 3 "Clutch over temperature" ;
VAL_ 1131 GBPositoionDisplay_46Bh 0 "NO Display" 1 "Display P" 2 "Display R" 3 "Display N" 4 "Display D" 5 "Display M1" 6 "Display M2" 7 "Display M3" 8 "Display M4" 9 "Display M5" 10 "Display M6" 11 "Display M7" 12 "Low" 13 "Display M1+" 14 "Display M2+" 15 "Display M3+" 16 "Display M4+" 17 "Display M5+" 18 "Display M6+" 19 "Display M7+" 20 "Display M2-" 21 "Display M3-" 22 "Display M4-" 23 "Display M5-" 24 "Display M6-" 25 "Display M7-" 26 "Display M8" 27 "Display M9" 28 "Display M8+" 29 "Display M8-" 30 "Display M9-" ;
VAL_ 1060 InforDisplay_424h 0 "No_display" 1 "Pressed_unlock_button" 2 "Pressed_brake_pedal" 3 "Positon_P_only_at_stop" 4 "Speed_too_high_can't_shift" 5 "Please_put_the_gearshift_dial_back_to_the_righ" 6 "Shift_to_or_out_Gear_P_with_Engine_Start" 7 "Pengagementmalfunction" ;
VAL_ 1129 EngineSpeedValidData_469h 0 "Valid" 1 "Not valid" ;
VAL_ 1128 PromptMesg_468h 0 "Not Active" 1 "Off" 2 "Active" ;
VAL_ 1018 FLZCU_KeyDriveModememory_3FAh 0 "Not_Active" 1 "Remember" 2 "No_Remember" ;
VAL_ 1018 FLZCU_DriveModeChangeFail_3FAh 0 "NOT FAI" 1 "FAIL" ;
VAL_ 1018 FLZCU_DraggingModeRemind_3FAh 0 "Not_Active" 1 "Enter" 2 "Working" 3 "Exit" 4 "Reserved" 5 "Reserved" 6 "Reserved" 7 "Reserved" ;
VAL_ 1018 FLZCU_CCOSwtFed_3FAh 0 "Not_Active" 1 "Active" 2 "Stand_by" 3 "Failed" ;
VAL_ 1018 FLZCU_CCO_TextDisp_3FAh 0 "No_Warn" 1 "Please_Release_EPB" 2 "Please_Slow_Down" 3 "Please_Close_ Door and Belt" 4 "Please_Open in D" 5 "Please_Close_APA/ACC/CC" 6 "Please_Exit_HDC" 7 "Please_Switch to Mud/Sand/Rock" 8 "Reduce_Speed_Below 12kph" 9 "Please_Close_CCO" ;
VAL_ 1018 FLZCU_DriveMode_3FAh 0 "Not Active" 1 "ECO" 2 "Normal" 3 "Sport" 4 "Snow" 5 "Off Road" 6 "Individual" 7 "Energy-saving hybrid" 8 "Sand" 9 "AI" 10 "Wade" 11 "Rock" 12 "Mud" 13 "Xmode" ;
VAL_ 1123 ISS_Switch_Sts_463h 0 "Not Active" 1 "ISS_Switch_Off" 2 "ISS_Switch_On" ;
